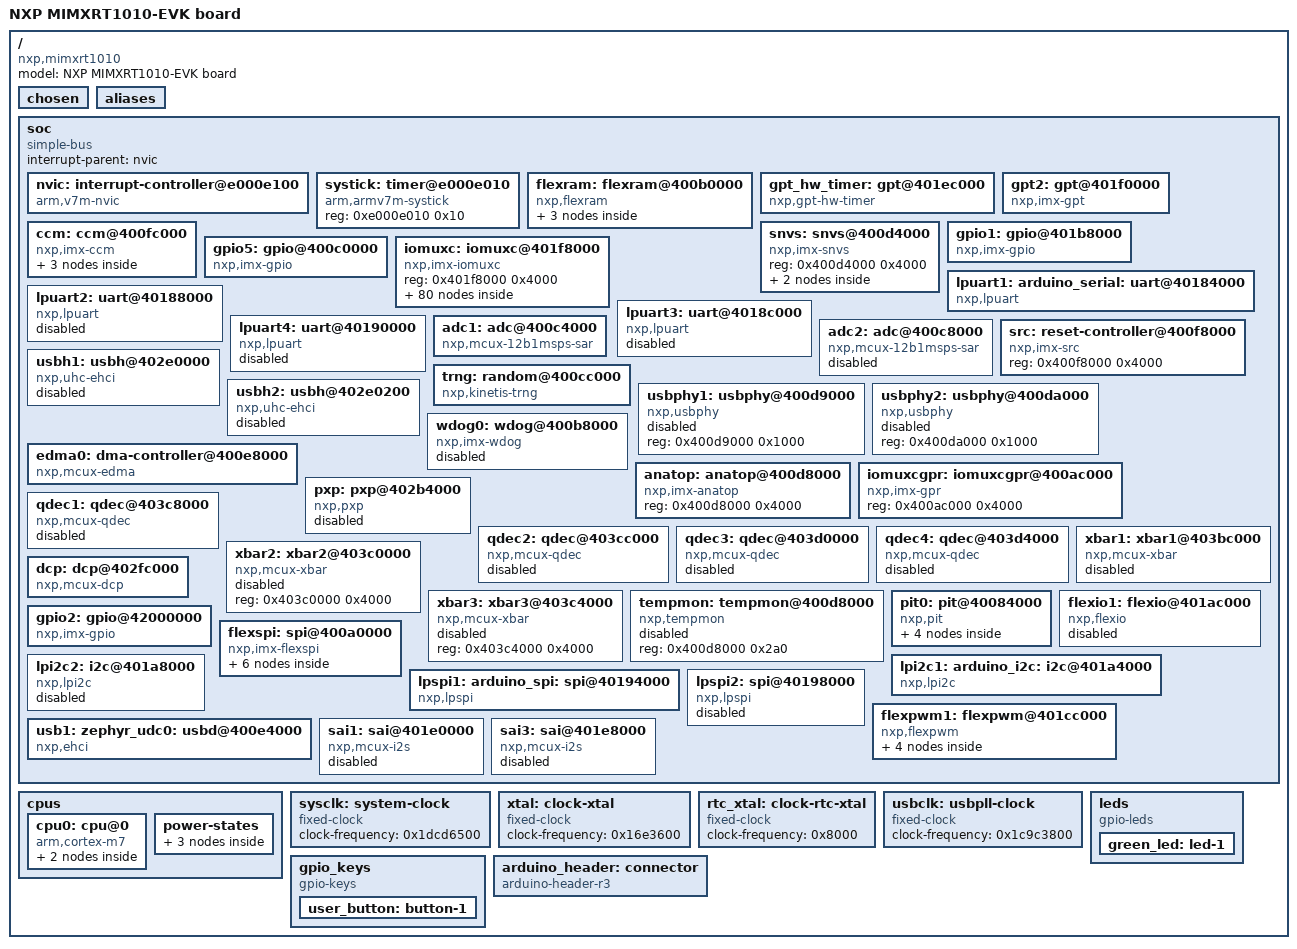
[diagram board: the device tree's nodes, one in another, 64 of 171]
/dts-v1/;

/* node '/' defined in zephyr/dts/common/skeleton.dtsi:9 */
/ {
	#address-cells = < 0x1 >;           /* in zephyr/dts/common/skeleton.dtsi:10 */
	#size-cells = < 0x1 >;              /* in zephyr/dts/common/skeleton.dtsi:11 */
	model = "NXP MIMXRT1010-EVK board"; /* in zephyr/boards/nxp/mimxrt1010_evk/mimxrt1010_evk.dts:16 */
	compatible = "nxp,mimxrt1010";      /* in zephyr/boards/nxp/mimxrt1010_evk/mimxrt1010_evk.dts:17 */

	/* node '/chosen' defined in zephyr/dts/common/skeleton.dtsi:13 */
	chosen {
		zephyr,entropy = &trng;                   /* in zephyr/dts/arm/nxp/nxp_rt10xx.dtsi:23 */
		zephyr,sram = &ocram;                     /* in zephyr/boards/nxp/mimxrt1010_evk/mimxrt1010_evk.dts:27 */
		zephyr,itcm = &itcm;                      /* in zephyr/boards/nxp/mimxrt1010_evk/mimxrt1010_evk.dts:28 */
		zephyr,dtcm = &dtcm;                      /* in zephyr/boards/nxp/mimxrt1010_evk/mimxrt1010_evk.dts:29 */
		zephyr,console = &lpuart1;                /* in zephyr/boards/nxp/mimxrt1010_evk/mimxrt1010_evk.dts:30 */
		zephyr,shell-uart = &lpuart1;             /* in zephyr/boards/nxp/mimxrt1010_evk/mimxrt1010_evk.dts:31 */
		zephyr,flash = &at25sf128a;               /* in zephyr/boards/nxp/mimxrt1010_evk/mimxrt1010_evk.dts:32 */
		zephyr,flash-controller = &at25sf128a;    /* in zephyr/boards/nxp/mimxrt1010_evk/mimxrt1010_evk.dts:33 */
		zephyr,code-partition = &slot0_partition; /* in zephyr/boards/nxp/mimxrt1010_evk/mimxrt1010_evk.dts:34 */
		zephyr,uart-mcumgr = &lpuart1;            /* in zephyr/boards/nxp/mimxrt1010_evk/mimxrt1010_evk.dts:35 */
	};

	/* node '/aliases' defined in zephyr/dts/common/skeleton.dtsi:15 */
	aliases {
		die-temp0 = &tempmon;           /* in zephyr/dts/arm/nxp/nxp_rt10xx.dtsi:19 */
		led0 = &green_led;              /* in zephyr/boards/nxp/mimxrt1010_evk/mimxrt1010_evk.dts:20 */
		sw0 = &user_button;             /* in zephyr/boards/nxp/mimxrt1010_evk/mimxrt1010_evk.dts:21 */
		mcuboot-button0 = &user_button; /* in zephyr/boards/nxp/mimxrt1010_evk/mimxrt1010_evk.dts:22 */
		rtc = &counter_rtc;             /* in zephyr/boards/nxp/mimxrt1010_evk/mimxrt1010_evk.dts:23 */
	};

	/* node '/soc' defined in zephyr/dts/arm/armv7-m.dtsi:6 */
	soc {
		#address-cells = < 0x1 >;     /* in zephyr/dts/arm/armv7-m.dtsi:7 */
		#size-cells = < 0x1 >;        /* in zephyr/dts/arm/armv7-m.dtsi:8 */
		compatible = "simple-bus";    /* in zephyr/dts/arm/armv7-m.dtsi:9 */
		interrupt-parent = < &nvic >; /* in zephyr/dts/arm/armv7-m.dtsi:10 */
		ranges;                       /* in zephyr/dts/arm/armv7-m.dtsi:11 */

		/* node '/soc/interrupt-controller@e000e100' defined in zephyr/dts/arm/armv7-m.dtsi:13 */
		nvic: interrupt-controller@e000e100 {
			#address-cells = < 0x1 >;            /* in zephyr/dts/arm/armv7-m.dtsi:14 */
			compatible = "arm,v7m-nvic";         /* in zephyr/dts/arm/armv7-m.dtsi:15 */
			reg = < 0xe000e100 0xc00 >;          /* in zephyr/dts/arm/armv7-m.dtsi:16 */
			interrupt-controller;                /* in zephyr/dts/arm/armv7-m.dtsi:17 */
			#interrupt-cells = < 0x2 >;          /* in zephyr/dts/arm/armv7-m.dtsi:18 */
			arm,num-irq-priority-bits = < 0x4 >; /* in zephyr/dts/arm/nxp/nxp_rt10xx.dtsi:1231 */
			phandle = < 0x1 >;                   /* in zephyr/dts/arm/armv7-m.dtsi:10 */
		};

		/* node '/soc/timer@e000e010' defined in zephyr/dts/arm/armv7-m.dtsi:21 */
		systick: timer@e000e010 {
			compatible = "arm,armv7m-systick"; /* in zephyr/dts/arm/armv7-m.dtsi:22 */
			reg = < 0xe000e010 0x10 >;         /* in zephyr/dts/arm/armv7-m.dtsi:23 */
			status = "okay";                   /* in zephyr/boards/nxp/mimxrt1010_evk/mimxrt1010_evk.dts:192 */
		};

		/* node '/soc/flexram@400b0000' defined in zephyr/dts/arm/nxp/nxp_rt10xx.dtsi:101 */
		flexram: flexram@400b0000 {
			compatible = "nxp,flexram";      /* in zephyr/dts/arm/nxp/nxp_rt10xx.dtsi:102 */
			reg = < 0x400b0000 0x4000 >;     /* in zephyr/dts/arm/nxp/nxp_rt10xx.dtsi:103 */
			interrupts = < 0x26 0x0 >;       /* in zephyr/dts/arm/nxp/nxp_rt10xx.dtsi:104 */
			#address-cells = < 0x1 >;        /* in zephyr/dts/arm/nxp/nxp_rt10xx.dtsi:106 */
			#size-cells = < 0x1 >;           /* in zephyr/dts/arm/nxp/nxp_rt10xx.dtsi:107 */
			status = "okay";                 /* in zephyr/dts/arm/nxp/nxp_rt10xx.dtsi:109 */
			flexram,bank-size = < 0x20 >;    /* in zephyr/dts/arm/nxp/nxp_rt10xx.dtsi:111 */
			flexram,num-ram-banks = < 0x4 >; /* in zephyr/dts/arm/nxp/nxp_rt1010.dtsi:10 */

			/* node '/soc/flexram@400b0000/itcm@0' defined in zephyr/dts/arm/nxp/nxp_rt10xx.dtsi:113 */
			itcm: itcm@0 {
				compatible = "zephyr,memory-region",
				             "nxp,imx-itcm";         /* in zephyr/dts/arm/nxp/nxp_rt10xx.dtsi:114 */
				zephyr,memory-region = "ITCM";       /* in zephyr/dts/arm/nxp/nxp_rt10xx.dtsi:116 */
				reg = < 0x0 0x8000 >;                /* in zephyr/dts/arm/nxp/nxp_rt1010.dtsi:18 */
			};

			/* node '/soc/flexram@400b0000/dtcm@20000000' defined in zephyr/dts/arm/nxp/nxp_rt10xx.dtsi:119 */
			dtcm: dtcm@20000000 {
				compatible = "zephyr,memory-region",
				             "nxp,imx-dtcm";         /* in zephyr/dts/arm/nxp/nxp_rt10xx.dtsi:120 */
				zephyr,memory-region = "DTCM";       /* in zephyr/dts/arm/nxp/nxp_rt10xx.dtsi:122 */
				reg = < 0x20000000 0x8000 >;         /* in zephyr/dts/arm/nxp/nxp_rt1010.dtsi:22 */
			};

			/* node '/soc/flexram@400b0000/ocram@20200000' defined in zephyr/dts/arm/nxp/nxp_rt10xx.dtsi:125 */
			ocram: ocram@20200000 {
				compatible = "zephyr,memory-region",
				             "mmio-sram";            /* in zephyr/dts/arm/nxp/nxp_rt10xx.dtsi:126 */
				zephyr,memory-region = "OCRAM";      /* in zephyr/dts/arm/nxp/nxp_rt10xx.dtsi:128 */
				reg = < 0x20200000 0x10000 >;        /* in zephyr/dts/arm/nxp/nxp_rt1010.dtsi:26 */
			};
		};

		/* node '/soc/gpt@401ec000' defined in zephyr/dts/arm/nxp/nxp_rt10xx.dtsi:165 */
		gpt_hw_timer: gpt@401ec000 {
			compatible = "nxp,gpt-hw-timer"; /* in zephyr/dts/arm/nxp/nxp_rt10xx.dtsi:166 */
			reg = < 0x401ec000 0x4000 >;     /* in zephyr/dts/arm/nxp/nxp_rt10xx.dtsi:167 */
			interrupts = < 0x1e 0x0 >;       /* in zephyr/dts/arm/nxp/nxp_rt1010.dtsi:46 */
			status = "okay";                 /* in zephyr/boards/nxp/mimxrt1010_evk/mimxrt1010_evk.dts:188 */
		};

		/* node '/soc/gpt@401f0000' defined in zephyr/dts/arm/nxp/nxp_rt10xx.dtsi:172 */
		gpt2: gpt@401f0000 {
			compatible = "nxp,imx-gpt";        /* in zephyr/dts/arm/nxp/nxp_rt10xx.dtsi:173 */
			reg = < 0x401f0000 0x4000 >;       /* in zephyr/dts/arm/nxp/nxp_rt10xx.dtsi:174 */
			clocks = < &ccm 0xa00 0x68 0x18 >; /* in zephyr/dts/arm/nxp/nxp_rt10xx.dtsi:177 */
			interrupts = < 0x1f 0x0 >;         /* in zephyr/dts/arm/nxp/nxp_rt1010.dtsi:50 */
			gptfreq = < 0xbebc20 >;            /* in zephyr/dts/arm/nxp/nxp_rt1010.dtsi:51 */
		};

		/* node '/soc/ccm@400fc000' defined in zephyr/dts/arm/nxp/nxp_rt10xx.dtsi:304 */
		ccm: ccm@400fc000 {
			compatible = "nxp,imx-ccm";  /* in zephyr/dts/arm/nxp/nxp_rt10xx.dtsi:305 */
			reg = < 0x400fc000 0x4000 >; /* in zephyr/dts/arm/nxp/nxp_rt10xx.dtsi:306 */
			clocks = < &xtal >,
			         < &rtc_xtal >;      /* in zephyr/dts/arm/nxp/nxp_rt10xx.dtsi:307 */
			clock-names = "xtal",
			              "rtc-xtal";    /* in zephyr/dts/arm/nxp/nxp_rt10xx.dtsi:308 */
			#clock-cells = < 0x3 >;      /* in zephyr/dts/arm/nxp/nxp_rt10xx.dtsi:337 */
			phandle = < 0x2 >;           /* in zephyr/dts/arm/nxp/nxp_rt10xx.dtsi:177 */

			/* node '/soc/ccm@400fc000/ahb-podf' defined in zephyr/dts/arm/nxp/nxp_rt10xx.dtsi:316 */
			ahb-podf {
				compatible = "fixed-factor-clock"; /* in zephyr/dts/arm/nxp/nxp_rt10xx.dtsi:317 */
				clock-div = < 0x1 >;               /* in zephyr/dts/arm/nxp/nxp_rt10xx.dtsi:318 */
				#clock-cells = < 0x0 >;            /* in zephyr/dts/arm/nxp/nxp_rt10xx.dtsi:319 */
			};

			/* node '/soc/ccm@400fc000/ipg-podf' defined in zephyr/dts/arm/nxp/nxp_rt10xx.dtsi:322 */
			ipg-podf {
				compatible = "fixed-factor-clock"; /* in zephyr/dts/arm/nxp/nxp_rt10xx.dtsi:323 */
				#clock-cells = < 0x0 >;            /* in zephyr/dts/arm/nxp/nxp_rt10xx.dtsi:325 */
				clock-div = < 0x4 >;               /* in zephyr/dts/arm/nxp/nxp_rt1010.dtsi:33 */
			};

			/* node '/soc/ccm@400fc000/sys-pll' defined in zephyr/dts/arm/nxp/nxp_rt10xx.dtsi:328 */
			sys-pll {
				compatible = "nxp,imx-ccm-fnpll"; /* in zephyr/dts/arm/nxp/nxp_rt10xx.dtsi:329 */
				loop-div = < 0x16 >;              /* in zephyr/dts/arm/nxp/nxp_rt10xx.dtsi:330 */
				numerator = < 0x0 >;              /* in zephyr/dts/arm/nxp/nxp_rt10xx.dtsi:331 */
				denominator = < 0x1 >;            /* in zephyr/dts/arm/nxp/nxp_rt10xx.dtsi:332 */
				src = < 0x0 >;                    /* in zephyr/dts/arm/nxp/nxp_rt10xx.dtsi:333 */
				#clock-cells = < 0x0 >;           /* in zephyr/dts/arm/nxp/nxp_rt10xx.dtsi:334 */
			};
		};

		/* node '/soc/snvs@400d4000' defined in zephyr/dts/arm/nxp/nxp_rt10xx.dtsi:340 */
		snvs: snvs@400d4000 {
			compatible = "nxp,imx-snvs"; /* in zephyr/dts/arm/nxp/nxp_rt10xx.dtsi:341 */
			reg = < 0x400d4000 0x4000 >; /* in zephyr/dts/arm/nxp/nxp_rt10xx.dtsi:342 */

			/* node '/soc/snvs@400d4000/rtc' defined in zephyr/dts/arm/nxp/nxp_rt10xx.dtsi:344 */
			snvs_rtc: rtc {
				compatible = "nxp,imx-snvs-rtc"; /* in zephyr/dts/arm/nxp/nxp_rt10xx.dtsi:345 */
				interrupts = < 0x2e 0x0 >;       /* in zephyr/dts/arm/nxp/nxp_rt10xx.dtsi:346 */
				wakeup-source;                   /* in zephyr/dts/arm/nxp/nxp_rt10xx.dtsi:347 */

				/* node '/soc/snvs@400d4000/rtc/counter_rtc' defined in zephyr/dts/arm/nxp/nxp_rt10xx.dtsi:349 */
				counter_rtc: counter_rtc {
					compatible = "zephyr,rtc-counter"; /* in zephyr/dts/arm/nxp/nxp_rt10xx.dtsi:350 */
					alarms-count = < 0x2 >;            /* in zephyr/dts/arm/nxp/nxp_rt10xx.dtsi:351 */
					status = "okay";                   /* in zephyr/boards/nxp/mimxrt1010_evk/mimxrt1010_evk.dts:200 */
				};
			};
		};

		/* node '/soc/gpio@401b8000' defined in zephyr/dts/arm/nxp/nxp_rt10xx.dtsi:357 */
		gpio1: gpio@401b8000 {
			compatible = "nxp,imx-gpio";                  /* in zephyr/dts/arm/nxp/nxp_rt10xx.dtsi:358 */
			reg = < 0x401b8000 0x4000 >;                  /* in zephyr/dts/arm/nxp/nxp_rt10xx.dtsi:359 */
			gpio-controller;                              /* in zephyr/dts/arm/nxp/nxp_rt10xx.dtsi:361 */
			#gpio-cells = < 0x2 >;                        /* in zephyr/dts/arm/nxp/nxp_rt10xx.dtsi:362 */
			interrupts = < 0x46 0x0 >,
			             < 0x47 0x0 >;                    /* in zephyr/dts/arm/nxp/nxp_rt1010.dtsi:38 */
			pinmux = < &iomuxc_gpio_00_gpiomux_io00 >,
			         < &iomuxc_gpio_01_gpiomux_io01 >,
			         < &iomuxc_gpio_02_gpiomux_io02 >,
			         < &iomuxc_gpio_03_gpiomux_io03 >,
			         < &iomuxc_gpio_04_gpiomux_io04 >,
			         < &iomuxc_gpio_05_gpiomux_io05 >,
			         < &iomuxc_gpio_06_gpiomux_io06 >,
			         < &iomuxc_gpio_07_gpiomux_io07 >,
			         < &iomuxc_gpio_08_gpiomux_io08 >,
			         < &iomuxc_gpio_09_gpiomux_io09 >,
			         < &iomuxc_gpio_10_gpiomux_io10 >,
			         < &iomuxc_gpio_11_gpiomux_io11 >,
			         < &iomuxc_gpio_12_gpiomux_io12 >,
			         < &iomuxc_gpio_13_gpiomux_io13 >,
			         < &iomuxc_gpio_ad_00_gpiomux_io14 >,
			         < &iomuxc_gpio_ad_01_gpiomux_io15 >,
			         < &iomuxc_gpio_ad_02_gpiomux_io16 >,
			         < &iomuxc_gpio_ad_03_gpiomux_io17 >,
			         < &iomuxc_gpio_ad_04_gpiomux_io18 >,
			         < &iomuxc_gpio_ad_05_gpiomux_io19 >,
			         < &iomuxc_gpio_ad_06_gpiomux_io20 >,
			         < &iomuxc_gpio_ad_07_gpiomux_io21 >,
			         < &iomuxc_gpio_ad_08_gpiomux_io22 >,
			         < &iomuxc_gpio_ad_09_gpiomux_io23 >,
			         < &iomuxc_gpio_ad_10_gpiomux_io24 >,
			         < &iomuxc_gpio_ad_11_gpiomux_io25 >,
			         < &iomuxc_gpio_ad_12_gpiomux_io26 >,
			         < &iomuxc_gpio_ad_13_gpiomux_io27 >,
			         < &iomuxc_gpio_ad_14_gpiomux_io28 >; /* in zephyr/dts/arm/nxp/nxp_rt1010.dtsi:360 */
			phandle = < 0x51 >;                           /* in zephyr/boards/nxp/mimxrt1010_evk/mimxrt1010_evk.dts:42 */
		};

		/* node '/soc/gpio@400c0000' defined in zephyr/dts/arm/nxp/nxp_rt10xx.dtsi:389 */
		gpio5: gpio@400c0000 {
			compatible = "nxp,imx-gpio";                      /* in zephyr/dts/arm/nxp/nxp_rt10xx.dtsi:390 */
			reg = < 0x400c0000 0x4000 >;                      /* in zephyr/dts/arm/nxp/nxp_rt10xx.dtsi:391 */
			gpio-controller;                                  /* in zephyr/dts/arm/nxp/nxp_rt10xx.dtsi:393 */
			#gpio-cells = < 0x2 >;                            /* in zephyr/dts/arm/nxp/nxp_rt10xx.dtsi:394 */
			interrupts = < 0x49 0x0 >;                        /* in zephyr/dts/arm/nxp/nxp_rt1010.dtsi:42 */
			pinmux = < &iomuxc_snvs_pmic_on_req_gpio5_io00 >; /* in zephyr/dts/arm/nxp/nxp_rt1010.dtsi:392 */
		};

		/* node '/soc/iomuxc@401f8000' defined in zephyr/dts/arm/nxp/nxp_rt10xx.dtsi:473 */
		iomuxc: iomuxc@401f8000 {
			compatible = "nxp,imx-iomuxc"; /* in zephyr/dts/arm/nxp/nxp_rt10xx.dtsi:474 */
			reg = < 0x401f8000 0x4000 >;   /* in zephyr/dts/arm/nxp/nxp_rt10xx.dtsi:475 */
			status = "okay";               /* in zephyr/dts/arm/nxp/nxp_rt10xx.dtsi:476 */

			/* node '/soc/iomuxc@401f8000/pinctrl' defined in zephyr/dts/arm/nxp/nxp_rt10xx.dtsi:478 */
			pinctrl: pinctrl {
				status = "okay";                    /* in zephyr/dts/arm/nxp/nxp_rt10xx.dtsi:479 */
				compatible = "nxp,mcux-rt-pinctrl"; /* in zephyr/dts/arm/nxp/nxp_rt10xx.dtsi:480 */

				/* node '/soc/iomuxc@401f8000/pinctrl/pinmux_adc1' defined in zephyr/boards/nxp/mimxrt1010_evk/mimxrt1010_evk-pinctrl.dtsi:13 */
				pinmux_adc1: pinmux_adc1 {
					phandle = < 0x39 >; /* in zephyr/boards/nxp/mimxrt1010_evk/mimxrt1010_evk.dts:170 */

					/* node '/soc/iomuxc@401f8000/pinctrl/pinmux_adc1/group0' defined in zephyr/boards/nxp/mimxrt1010_evk/mimxrt1010_evk-pinctrl.dtsi:14 */
					group0 {
						pinmux = < &iomuxc_gpio_ad_01_adc1_in1 >,
						         < &iomuxc_gpio_ad_02_adc1_in2 >; /* in zephyr/boards/nxp/mimxrt1010_evk/mimxrt1010_evk-pinctrl.dtsi:15 */
						drive-strength = "r0-4";                  /* in zephyr/boards/nxp/mimxrt1010_evk/mimxrt1010_evk-pinctrl.dtsi:17 */
						slew-rate = "slow";                       /* in zephyr/boards/nxp/mimxrt1010_evk/mimxrt1010_evk-pinctrl.dtsi:18 */
						nxp,speed = "100-mhz";                    /* in zephyr/boards/nxp/mimxrt1010_evk/mimxrt1010_evk-pinctrl.dtsi:19 */
					};
				};

				/* node '/soc/iomuxc@401f8000/pinctrl/pinmux_lpi2c1' defined in zephyr/boards/nxp/mimxrt1010_evk/mimxrt1010_evk-pinctrl.dtsi:23 */
				pinmux_lpi2c1: pinmux_lpi2c1 {
					phandle = < 0x49 >; /* in zephyr/boards/nxp/mimxrt1010_evk/mimxrt1010_evk.dts:143 */

					/* node '/soc/iomuxc@401f8000/pinctrl/pinmux_lpi2c1/group0' defined in zephyr/boards/nxp/mimxrt1010_evk/mimxrt1010_evk-pinctrl.dtsi:24 */
					group0 {
						pinmux = < &iomuxc_gpio_01_lpi2c1_sda >,
						         < &iomuxc_gpio_02_lpi2c1_scl >; /* in zephyr/boards/nxp/mimxrt1010_evk/mimxrt1010_evk-pinctrl.dtsi:25 */
						drive-strength = "r0-4";                 /* in zephyr/boards/nxp/mimxrt1010_evk/mimxrt1010_evk-pinctrl.dtsi:26 */
						drive-open-drain;                        /* in zephyr/boards/nxp/mimxrt1010_evk/mimxrt1010_evk-pinctrl.dtsi:27 */
						slew-rate = "slow";                      /* in zephyr/boards/nxp/mimxrt1010_evk/mimxrt1010_evk-pinctrl.dtsi:28 */
						nxp,speed = "100-mhz";                   /* in zephyr/boards/nxp/mimxrt1010_evk/mimxrt1010_evk-pinctrl.dtsi:29 */
						input-enable;                            /* in zephyr/boards/nxp/mimxrt1010_evk/mimxrt1010_evk-pinctrl.dtsi:30 */
					};
				};

				/* node '/soc/iomuxc@401f8000/pinctrl/pinmux_lpspi1' defined in zephyr/boards/nxp/mimxrt1010_evk/mimxrt1010_evk-pinctrl.dtsi:34 */
				pinmux_lpspi1: pinmux_lpspi1 {
					phandle = < 0x4a >; /* in zephyr/boards/nxp/mimxrt1010_evk/mimxrt1010_evk.dts:160 */

					/* node '/soc/iomuxc@401f8000/pinctrl/pinmux_lpspi1/group0' defined in zephyr/boards/nxp/mimxrt1010_evk/mimxrt1010_evk-pinctrl.dtsi:35 */
					group0 {
						pinmux = < &iomuxc_gpio_ad_06_lpspi1_sck >,
						         < &iomuxc_gpio_ad_05_lpspi1_pcs0 >,
						         < &iomuxc_gpio_ad_04_lpspi1_sdo >,
						         < &iomuxc_gpio_ad_03_lpspi1_sdi >;  /* in zephyr/boards/nxp/mimxrt1010_evk/mimxrt1010_evk-pinctrl.dtsi:36 */
						drive-strength = "r0-4";                     /* in zephyr/boards/nxp/mimxrt1010_evk/mimxrt1010_evk-pinctrl.dtsi:40 */
						slew-rate = "slow";                          /* in zephyr/boards/nxp/mimxrt1010_evk/mimxrt1010_evk-pinctrl.dtsi:41 */
						nxp,speed = "100-mhz";                       /* in zephyr/boards/nxp/mimxrt1010_evk/mimxrt1010_evk-pinctrl.dtsi:42 */
					};
				};

				/* node '/soc/iomuxc@401f8000/pinctrl/pinmux_lpuart1' defined in zephyr/boards/nxp/mimxrt1010_evk/mimxrt1010_evk-pinctrl.dtsi:47 */
				pinmux_lpuart1: pinmux_lpuart1 {
					phandle = < 0x35 >; /* in zephyr/boards/nxp/mimxrt1010_evk/mimxrt1010_evk.dts:150 */

					/* node '/soc/iomuxc@401f8000/pinctrl/pinmux_lpuart1/group0' defined in zephyr/boards/nxp/mimxrt1010_evk/mimxrt1010_evk-pinctrl.dtsi:48 */
					group0 {
						pinmux = < &iomuxc_gpio_09_lpuart1_rxd >,
						         < &iomuxc_gpio_10_lpuart1_txd >; /* in zephyr/boards/nxp/mimxrt1010_evk/mimxrt1010_evk-pinctrl.dtsi:49 */
						drive-strength = "r0-4";                  /* in zephyr/boards/nxp/mimxrt1010_evk/mimxrt1010_evk-pinctrl.dtsi:51 */
						slew-rate = "slow";                       /* in zephyr/boards/nxp/mimxrt1010_evk/mimxrt1010_evk-pinctrl.dtsi:52 */
						nxp,speed = "100-mhz";                    /* in zephyr/boards/nxp/mimxrt1010_evk/mimxrt1010_evk-pinctrl.dtsi:53 */
					};
				};

				/* node '/soc/iomuxc@401f8000/pinctrl/pinmux_lpuart1_sleep' defined in zephyr/boards/nxp/mimxrt1010_evk/mimxrt1010_evk-pinctrl.dtsi:57 */
				pinmux_lpuart1_sleep: pinmux_lpuart1_sleep {
					phandle = < 0x36 >; /* in zephyr/boards/nxp/mimxrt1010_evk/mimxrt1010_evk.dts:151 */

					/* node '/soc/iomuxc@401f8000/pinctrl/pinmux_lpuart1_sleep/group0' defined in zephyr/boards/nxp/mimxrt1010_evk/mimxrt1010_evk-pinctrl.dtsi:58 */
					group0 {
						pinmux = < &iomuxc_gpio_09_gpiomux_io09 >; /* in zephyr/boards/nxp/mimxrt1010_evk/mimxrt1010_evk-pinctrl.dtsi:59 */
						drive-strength = "r0-4";                   /* in zephyr/boards/nxp/mimxrt1010_evk/mimxrt1010_evk-pinctrl.dtsi:60 */
						bias-pull-up;                              /* in zephyr/boards/nxp/mimxrt1010_evk/mimxrt1010_evk-pinctrl.dtsi:61 */
						bias-pull-up-value = "100k";               /* in zephyr/boards/nxp/mimxrt1010_evk/mimxrt1010_evk-pinctrl.dtsi:62 */
						slew-rate = "slow";                        /* in zephyr/boards/nxp/mimxrt1010_evk/mimxrt1010_evk-pinctrl.dtsi:63 */
						nxp,speed = "100-mhz";                     /* in zephyr/boards/nxp/mimxrt1010_evk/mimxrt1010_evk-pinctrl.dtsi:64 */
					};

					/* node '/soc/iomuxc@401f8000/pinctrl/pinmux_lpuart1_sleep/group1' defined in zephyr/boards/nxp/mimxrt1010_evk/mimxrt1010_evk-pinctrl.dtsi:67 */
					group1 {
						pinmux = < &iomuxc_gpio_10_lpuart1_txd >; /* in zephyr/boards/nxp/mimxrt1010_evk/mimxrt1010_evk-pinctrl.dtsi:68 */
						drive-strength = "r0-4";                  /* in zephyr/boards/nxp/mimxrt1010_evk/mimxrt1010_evk-pinctrl.dtsi:69 */
						slew-rate = "slow";                       /* in zephyr/boards/nxp/mimxrt1010_evk/mimxrt1010_evk-pinctrl.dtsi:70 */
						nxp,speed = "100-mhz";                    /* in zephyr/boards/nxp/mimxrt1010_evk/mimxrt1010_evk-pinctrl.dtsi:71 */
					};
				};

				/* node '/soc/iomuxc@401f8000/pinctrl/pinmux_lpuart4' defined in zephyr/boards/nxp/mimxrt1010_evk/mimxrt1010_evk-pinctrl.dtsi:76 */
				pinmux_lpuart4: pinmux_lpuart4 {
					phandle = < 0x37 >; /* in zephyr/boards/nxp/mimxrt1010_evk/mimxrt1010_evk.dts:90 */

					/* node '/soc/iomuxc@401f8000/pinctrl/pinmux_lpuart4/group0' defined in zephyr/boards/nxp/mimxrt1010_evk/mimxrt1010_evk-pinctrl.dtsi:77 */
					group0 {
						pinmux = < &iomuxc_gpio_ad_01_lpuart4_rxd >,
						         < &iomuxc_gpio_ad_02_lpuart4_txd >; /* in zephyr/boards/nxp/mimxrt1010_evk/mimxrt1010_evk-pinctrl.dtsi:78 */
						drive-strength = "r0-4";                     /* in zephyr/boards/nxp/mimxrt1010_evk/mimxrt1010_evk-pinctrl.dtsi:80 */
						slew-rate = "slow";                          /* in zephyr/boards/nxp/mimxrt1010_evk/mimxrt1010_evk-pinctrl.dtsi:81 */
						nxp,speed = "100-mhz";                       /* in zephyr/boards/nxp/mimxrt1010_evk/mimxrt1010_evk-pinctrl.dtsi:82 */
					};
				};

				/* node '/soc/iomuxc@401f8000/pinctrl/pinmux_lpuart4_sleep' defined in zephyr/boards/nxp/mimxrt1010_evk/mimxrt1010_evk-pinctrl.dtsi:87 */
				pinmux_lpuart4_sleep: pinmux_lpuart4_sleep {
					phandle = < 0x38 >; /* in zephyr/boards/nxp/mimxrt1010_evk/mimxrt1010_evk.dts:91 */

					/* node '/soc/iomuxc@401f8000/pinctrl/pinmux_lpuart4_sleep/group0' defined in zephyr/boards/nxp/mimxrt1010_evk/mimxrt1010_evk-pinctrl.dtsi:88 */
					group0 {
						pinmux = < &iomuxc_gpio_ad_01_gpiomux_io15 >; /* in zephyr/boards/nxp/mimxrt1010_evk/mimxrt1010_evk-pinctrl.dtsi:89 */
						drive-strength = "r0-4";                      /* in zephyr/boards/nxp/mimxrt1010_evk/mimxrt1010_evk-pinctrl.dtsi:90 */
						bias-pull-up;                                 /* in zephyr/boards/nxp/mimxrt1010_evk/mimxrt1010_evk-pinctrl.dtsi:91 */
						bias-pull-up-value = "100k";                  /* in zephyr/boards/nxp/mimxrt1010_evk/mimxrt1010_evk-pinctrl.dtsi:92 */
						slew-rate = "slow";                           /* in zephyr/boards/nxp/mimxrt1010_evk/mimxrt1010_evk-pinctrl.dtsi:93 */
						nxp,speed = "100-mhz";                        /* in zephyr/boards/nxp/mimxrt1010_evk/mimxrt1010_evk-pinctrl.dtsi:94 */
					};

					/* node '/soc/iomuxc@401f8000/pinctrl/pinmux_lpuart4_sleep/group1' defined in zephyr/boards/nxp/mimxrt1010_evk/mimxrt1010_evk-pinctrl.dtsi:97 */
					group1 {
						pinmux = < &iomuxc_gpio_ad_02_lpuart4_txd >; /* in zephyr/boards/nxp/mimxrt1010_evk/mimxrt1010_evk-pinctrl.dtsi:98 */
						drive-strength = "r0-4";                     /* in zephyr/boards/nxp/mimxrt1010_evk/mimxrt1010_evk-pinctrl.dtsi:99 */
						slew-rate = "slow";                          /* in zephyr/boards/nxp/mimxrt1010_evk/mimxrt1010_evk-pinctrl.dtsi:100 */
						nxp,speed = "100-mhz";                       /* in zephyr/boards/nxp/mimxrt1010_evk/mimxrt1010_evk-pinctrl.dtsi:101 */
					};
				};

				/* node '/soc/iomuxc@401f8000/pinctrl/pinmux_sai1' defined in zephyr/boards/nxp/mimxrt1010_evk/mimxrt1010_evk-pinctrl.dtsi:105 */
				pinmux_sai1: pinmux_sai1 {
					phandle = < 0x4d >; /* in zephyr/boards/nxp/mimxrt1010_evk/mimxrt1010_evk.dts:175 */

					/* node '/soc/iomuxc@401f8000/pinctrl/pinmux_sai1/group0' defined in zephyr/boards/nxp/mimxrt1010_evk/mimxrt1010_evk-pinctrl.dtsi:106 */
					group0 {
						pinmux = < &iomuxc_gpio_08_sai1_mclk >,
						         < &iomuxc_gpio_03_sai1_rx_data0 >,
						         < &iomuxc_gpio_04_sai1_tx_data0 >,
						         < &iomuxc_gpio_07_sai1_tx_sync >,
						         < &iomuxc_gpio_06_sai1_tx_bclk >;  /* in zephyr/boards/nxp/mimxrt1010_evk/mimxrt1010_evk-pinctrl.dtsi:107 */
						drive-strength = "r0-4";                    /* in zephyr/boards/nxp/mimxrt1010_evk/mimxrt1010_evk-pinctrl.dtsi:112 */
						slew-rate = "slow";                         /* in zephyr/boards/nxp/mimxrt1010_evk/mimxrt1010_evk-pinctrl.dtsi:113 */
						nxp,speed = "100-mhz";                      /* in zephyr/boards/nxp/mimxrt1010_evk/mimxrt1010_evk-pinctrl.dtsi:114 */
					};
				};
			};

			/* node '/soc/iomuxc@401f8000/IOMUXC_GPIO_00_GPIOMUX_IO00' defined in modules/hal/nxp/dts/nxp/nxp_imx/rt/mimxrt1011dae5a-pinctrl.dtsi:24 */
			iomuxc_gpio_00_gpiomux_io00: IOMUXC_GPIO_00_GPIOMUX_IO00 {
				pinmux = < 0x401f80bc 0x5 0x0 0x0 0x401f816c >; /* in modules/hal/nxp/dts/nxp/nxp_imx/rt/mimxrt1011dae5a-pinctrl.dtsi:25 */
				phandle = < 0x5 >;                              /* in zephyr/dts/arm/nxp/nxp_rt1010.dtsi:360 */
			};

			/* node '/soc/iomuxc@401f8000/IOMUXC_GPIO_01_GPIOMUX_IO01' defined in modules/hal/nxp/dts/nxp/nxp_imx/rt/mimxrt1011dae5a-pinctrl.dtsi:42 */
			iomuxc_gpio_01_gpiomux_io01: IOMUXC_GPIO_01_GPIOMUX_IO01 {
				pinmux = < 0x401f80b8 0x5 0x0 0x0 0x401f8168 >; /* in modules/hal/nxp/dts/nxp/nxp_imx/rt/mimxrt1011dae5a-pinctrl.dtsi:43 */
				phandle = < 0x6 >;                              /* in zephyr/dts/arm/nxp/nxp_rt1010.dtsi:360 */
			};

			/* node '/soc/iomuxc@401f8000/IOMUXC_GPIO_01_LPI2C1_SDA' defined in modules/hal/nxp/dts/nxp/nxp_imx/rt/mimxrt1011dae5a-pinctrl.dtsi:48 */
			iomuxc_gpio_01_lpi2c1_sda: IOMUXC_GPIO_01_LPI2C1_SDA {
				pinmux = < 0x401f80b8 0x3 0x401f81c4 0x3 0x401f8168 >; /* in modules/hal/nxp/dts/nxp/nxp_imx/rt/mimxrt1011dae5a-pinctrl.dtsi:49 */
				phandle = < 0x25 >;                                    /* in zephyr/boards/nxp/mimxrt1010_evk/mimxrt1010_evk-pinctrl.dtsi:25 */
			};

			/* node '/soc/iomuxc@401f8000/IOMUXC_GPIO_02_GPIOMUX_IO02' defined in modules/hal/nxp/dts/nxp/nxp_imx/rt/mimxrt1011dae5a-pinctrl.dtsi:60 */
			iomuxc_gpio_02_gpiomux_io02: IOMUXC_GPIO_02_GPIOMUX_IO02 {
				pinmux = < 0x401f80b4 0x5 0x0 0x0 0x401f8164 >; /* in modules/hal/nxp/dts/nxp/nxp_imx/rt/mimxrt1011dae5a-pinctrl.dtsi:61 */
				phandle = < 0x7 >;                              /* in zephyr/dts/arm/nxp/nxp_rt1010.dtsi:360 */
			};

			/* node '/soc/iomuxc@401f8000/IOMUXC_GPIO_02_LPI2C1_SCL' defined in modules/hal/nxp/dts/nxp/nxp_imx/rt/mimxrt1011dae5a-pinctrl.dtsi:66 */
			iomuxc_gpio_02_lpi2c1_scl: IOMUXC_GPIO_02_LPI2C1_SCL {
				pinmux = < 0x401f80b4 0x3 0x401f81c0 0x3 0x401f8164 >; /* in modules/hal/nxp/dts/nxp/nxp_imx/rt/mimxrt1011dae5a-pinctrl.dtsi:67 */
				phandle = < 0x26 >;                                    /* in zephyr/boards/nxp/mimxrt1010_evk/mimxrt1010_evk-pinctrl.dtsi:25 */
			};

			/* node '/soc/iomuxc@401f8000/IOMUXC_GPIO_03_GPIOMUX_IO03' defined in modules/hal/nxp/dts/nxp/nxp_imx/rt/mimxrt1011dae5a-pinctrl.dtsi:78 */
			iomuxc_gpio_03_gpiomux_io03: IOMUXC_GPIO_03_GPIOMUX_IO03 {
				pinmux = < 0x401f80b0 0x5 0x0 0x0 0x401f8160 >; /* in modules/hal/nxp/dts/nxp/nxp_imx/rt/mimxrt1011dae5a-pinctrl.dtsi:79 */
				phandle = < 0x8 >;                              /* in zephyr/dts/arm/nxp/nxp_rt1010.dtsi:360 */
			};

			/* node '/soc/iomuxc@401f8000/IOMUXC_GPIO_03_SAI1_RX_DATA0' defined in modules/hal/nxp/dts/nxp/nxp_imx/rt/mimxrt1011dae5a-pinctrl.dtsi:84 */
			iomuxc_gpio_03_sai1_rx_data0: IOMUXC_GPIO_03_SAI1_RX_DATA0 {
				pinmux = < 0x401f80b0 0x0 0x0 0x0 0x401f8160 >; /* in modules/hal/nxp/dts/nxp/nxp_imx/rt/mimxrt1011dae5a-pinctrl.dtsi:85 */
				phandle = < 0x30 >;                             /* in zephyr/boards/nxp/mimxrt1010_evk/mimxrt1010_evk-pinctrl.dtsi:107 */
			};

			/* node '/soc/iomuxc@401f8000/IOMUXC_GPIO_04_GPIOMUX_IO04' defined in modules/hal/nxp/dts/nxp/nxp_imx/rt/mimxrt1011dae5a-pinctrl.dtsi:93 */
			iomuxc_gpio_04_gpiomux_io04: IOMUXC_GPIO_04_GPIOMUX_IO04 {
				pinmux = < 0x401f80ac 0x5 0x0 0x0 0x401f815c >; /* in modules/hal/nxp/dts/nxp/nxp_imx/rt/mimxrt1011dae5a-pinctrl.dtsi:94 */
				phandle = < 0x9 >;                              /* in zephyr/dts/arm/nxp/nxp_rt1010.dtsi:360 */
			};

			/* node '/soc/iomuxc@401f8000/IOMUXC_GPIO_04_SAI1_TX_DATA0' defined in modules/hal/nxp/dts/nxp/nxp_imx/rt/mimxrt1011dae5a-pinctrl.dtsi:99 */
			iomuxc_gpio_04_sai1_tx_data0: IOMUXC_GPIO_04_SAI1_TX_DATA0 {
				pinmux = < 0x401f80ac 0x0 0x0 0x0 0x401f815c >; /* in modules/hal/nxp/dts/nxp/nxp_imx/rt/mimxrt1011dae5a-pinctrl.dtsi:100 */
				phandle = < 0x31 >;                             /* in zephyr/boards/nxp/mimxrt1010_evk/mimxrt1010_evk-pinctrl.dtsi:107 */
			};

			/* node '/soc/iomuxc@401f8000/IOMUXC_GPIO_05_GPIOMUX_IO05' defined in modules/hal/nxp/dts/nxp/nxp_imx/rt/mimxrt1011dae5a-pinctrl.dtsi:108 */
			iomuxc_gpio_05_gpiomux_io05: IOMUXC_GPIO_05_GPIOMUX_IO05 {
				pinmux = < 0x401f80a8 0x5 0x0 0x0 0x401f8158 >; /* in modules/hal/nxp/dts/nxp/nxp_imx/rt/mimxrt1011dae5a-pinctrl.dtsi:109 */
				phandle = < 0xa >;                              /* in zephyr/dts/arm/nxp/nxp_rt1010.dtsi:360 */
			};

			/* node '/soc/iomuxc@401f8000/IOMUXC_GPIO_06_GPIOMUX_IO06' defined in modules/hal/nxp/dts/nxp/nxp_imx/rt/mimxrt1011dae5a-pinctrl.dtsi:126 */
			iomuxc_gpio_06_gpiomux_io06: IOMUXC_GPIO_06_GPIOMUX_IO06 {
				pinmux = < 0x401f80a4 0x5 0x0 0x0 0x401f8154 >; /* in modules/hal/nxp/dts/nxp/nxp_imx/rt/mimxrt1011dae5a-pinctrl.dtsi:127 */
				phandle = < 0xb >;                              /* in zephyr/dts/arm/nxp/nxp_rt1010.dtsi:360 */
			};

			/* node '/soc/iomuxc@401f8000/IOMUXC_GPIO_06_SAI1_TX_BCLK' defined in modules/hal/nxp/dts/nxp/nxp_imx/rt/mimxrt1011dae5a-pinctrl.dtsi:135 */
			iomuxc_gpio_06_sai1_tx_bclk: IOMUXC_GPIO_06_SAI1_TX_BCLK {
				pinmux = < 0x401f80a4 0x0 0x0 0x0 0x401f8154 >; /* in modules/hal/nxp/dts/nxp/nxp_imx/rt/mimxrt1011dae5a-pinctrl.dtsi:136 */
				phandle = < 0x33 >;                             /* in zephyr/boards/nxp/mimxrt1010_evk/mimxrt1010_evk-pinctrl.dtsi:107 */
			};

			/* node '/soc/iomuxc@401f8000/IOMUXC_GPIO_07_GPIOMUX_IO07' defined in modules/hal/nxp/dts/nxp/nxp_imx/rt/mimxrt1011dae5a-pinctrl.dtsi:144 */
			iomuxc_gpio_07_gpiomux_io07: IOMUXC_GPIO_07_GPIOMUX_IO07 {
				pinmux = < 0x401f80a0 0x5 0x0 0x0 0x401f8150 >; /* in modules/hal/nxp/dts/nxp/nxp_imx/rt/mimxrt1011dae5a-pinctrl.dtsi:145 */
				phandle = < 0xc >;                              /* in zephyr/dts/arm/nxp/nxp_rt1010.dtsi:360 */
			};

			/* node '/soc/iomuxc@401f8000/IOMUXC_GPIO_07_SAI1_TX_SYNC' defined in modules/hal/nxp/dts/nxp/nxp_imx/rt/mimxrt1011dae5a-pinctrl.dtsi:156 */
			iomuxc_gpio_07_sai1_tx_sync: IOMUXC_GPIO_07_SAI1_TX_SYNC {
				pinmux = < 0x401f80a0 0x0 0x0 0x0 0x401f8150 >; /* in modules/hal/nxp/dts/nxp/nxp_imx/rt/mimxrt1011dae5a-pinctrl.dtsi:157 */
				phandle = < 0x32 >;                             /* in zephyr/boards/nxp/mimxrt1010_evk/mimxrt1010_evk-pinctrl.dtsi:107 */
			};

			/* node '/soc/iomuxc@401f8000/IOMUXC_GPIO_08_GPIOMUX_IO08' defined in modules/hal/nxp/dts/nxp/nxp_imx/rt/mimxrt1011dae5a-pinctrl.dtsi:168 */
			iomuxc_gpio_08_gpiomux_io08: IOMUXC_GPIO_08_GPIOMUX_IO08 {
				pinmux = < 0x401f809c 0x5 0x0 0x0 0x401f814c >; /* in modules/hal/nxp/dts/nxp/nxp_imx/rt/mimxrt1011dae5a-pinctrl.dtsi:169 */
				phandle = < 0xd >;                              /* in zephyr/dts/arm/nxp/nxp_rt1010.dtsi:360 */
			};

			/* node '/soc/iomuxc@401f8000/IOMUXC_GPIO_08_SAI1_MCLK' defined in modules/hal/nxp/dts/nxp/nxp_imx/rt/mimxrt1011dae5a-pinctrl.dtsi:180 */
			iomuxc_gpio_08_sai1_mclk: IOMUXC_GPIO_08_SAI1_MCLK {
				pinmux = < 0x401f809c 0x0 0x0 0x0 0x401f814c >; /* in modules/hal/nxp/dts/nxp/nxp_imx/rt/mimxrt1011dae5a-pinctrl.dtsi:181 */
				phandle = < 0x2f >;                             /* in zephyr/boards/nxp/mimxrt1010_evk/mimxrt1010_evk-pinctrl.dtsi:107 */
			};

			/* node '/soc/iomuxc@401f8000/IOMUXC_GPIO_09_GPIOMUX_IO09' defined in modules/hal/nxp/dts/nxp/nxp_imx/rt/mimxrt1011dae5a-pinctrl.dtsi:189 */
			iomuxc_gpio_09_gpiomux_io09: IOMUXC_GPIO_09_GPIOMUX_IO09 {
				pinmux = < 0x401f8098 0x5 0x0 0x0 0x401f8148 >; /* in modules/hal/nxp/dts/nxp/nxp_imx/rt/mimxrt1011dae5a-pinctrl.dtsi:190 */
				phandle = < 0xe >;                              /* in zephyr/dts/arm/nxp/nxp_rt1010.dtsi:360 */
			};

			/* node '/soc/iomuxc@401f8000/IOMUXC_GPIO_09_LPUART1_RXD' defined in modules/hal/nxp/dts/nxp/nxp_imx/rt/mimxrt1011dae5a-pinctrl.dtsi:195 */
			iomuxc_gpio_09_lpuart1_rxd: IOMUXC_GPIO_09_LPUART1_RXD {
				pinmux = < 0x401f8098 0x0 0x401f81f0 0x1 0x401f8148 >; /* in modules/hal/nxp/dts/nxp/nxp_imx/rt/mimxrt1011dae5a-pinctrl.dtsi:196 */
				phandle = < 0x2b >;                                    /* in zephyr/boards/nxp/mimxrt1010_evk/mimxrt1010_evk-pinctrl.dtsi:49 */
			};

			/* node '/soc/iomuxc@401f8000/IOMUXC_GPIO_10_GPIOMUX_IO10' defined in modules/hal/nxp/dts/nxp/nxp_imx/rt/mimxrt1011dae5a-pinctrl.dtsi:210 */
			iomuxc_gpio_10_gpiomux_io10: IOMUXC_GPIO_10_GPIOMUX_IO10 {
				pinmux = < 0x401f8094 0x5 0x0 0x0 0x401f8144 >; /* in modules/hal/nxp/dts/nxp/nxp_imx/rt/mimxrt1011dae5a-pinctrl.dtsi:211 */
				phandle = < 0xf >;                              /* in zephyr/dts/arm/nxp/nxp_rt1010.dtsi:360 */
			};

			/* node '/soc/iomuxc@401f8000/IOMUXC_GPIO_10_LPUART1_TXD' defined in modules/hal/nxp/dts/nxp/nxp_imx/rt/mimxrt1011dae5a-pinctrl.dtsi:219 */
			iomuxc_gpio_10_lpuart1_txd: IOMUXC_GPIO_10_LPUART1_TXD {
				pinmux = < 0x401f8094 0x0 0x401f81f4 0x1 0x401f8144 >; /* in modules/hal/nxp/dts/nxp/nxp_imx/rt/mimxrt1011dae5a-pinctrl.dtsi:220 */
				phandle = < 0x2c >;                                    /* in zephyr/boards/nxp/mimxrt1010_evk/mimxrt1010_evk-pinctrl.dtsi:49 */
			};

			/* node '/soc/iomuxc@401f8000/IOMUXC_GPIO_11_GPIOMUX_IO11' defined in modules/hal/nxp/dts/nxp/nxp_imx/rt/mimxrt1011dae5a-pinctrl.dtsi:234 */
			iomuxc_gpio_11_gpiomux_io11: IOMUXC_GPIO_11_GPIOMUX_IO11 {
				pinmux = < 0x401f8090 0x5 0x0 0x0 0x401f8140 >; /* in modules/hal/nxp/dts/nxp/nxp_imx/rt/mimxrt1011dae5a-pinctrl.dtsi:235 */
				phandle = < 0x10 >;                             /* in zephyr/dts/arm/nxp/nxp_rt1010.dtsi:360 */
			};

			/* node '/soc/iomuxc@401f8000/IOMUXC_GPIO_12_GPIOMUX_IO12' defined in modules/hal/nxp/dts/nxp/nxp_imx/rt/mimxrt1011dae5a-pinctrl.dtsi:255 */
			iomuxc_gpio_12_gpiomux_io12: IOMUXC_GPIO_12_GPIOMUX_IO12 {
				pinmux = < 0x401f808c 0x5 0x0 0x0 0x401f813c >; /* in modules/hal/nxp/dts/nxp/nxp_imx/rt/mimxrt1011dae5a-pinctrl.dtsi:256 */
				phandle = < 0x11 >;                             /* in zephyr/dts/arm/nxp/nxp_rt1010.dtsi:360 */
			};

			/* node '/soc/iomuxc@401f8000/IOMUXC_GPIO_13_GPIOMUX_IO13' defined in modules/hal/nxp/dts/nxp/nxp_imx/rt/mimxrt1011dae5a-pinctrl.dtsi:279 */
			iomuxc_gpio_13_gpiomux_io13: IOMUXC_GPIO_13_GPIOMUX_IO13 {
				pinmux = < 0x401f8088 0x5 0x0 0x0 0x401f8138 >; /* in modules/hal/nxp/dts/nxp/nxp_imx/rt/mimxrt1011dae5a-pinctrl.dtsi:280 */
				phandle = < 0x12 >;                             /* in zephyr/dts/arm/nxp/nxp_rt1010.dtsi:360 */
			};

			/* node '/soc/iomuxc@401f8000/IOMUXC_GPIO_AD_00_GPIOMUX_IO14' defined in modules/hal/nxp/dts/nxp/nxp_imx/rt/mimxrt1011dae5a-pinctrl.dtsi:309 */
			iomuxc_gpio_ad_00_gpiomux_io14: IOMUXC_GPIO_AD_00_GPIOMUX_IO14 {
				pinmux = < 0x401f8048 0x5 0x0 0x0 0x401f80f8 >; /* in modules/hal/nxp/dts/nxp/nxp_imx/rt/mimxrt1011dae5a-pinctrl.dtsi:310 */
				phandle = < 0x13 >;                             /* in zephyr/dts/arm/nxp/nxp_rt1010.dtsi:360 */
			};

			/* node '/soc/iomuxc@401f8000/IOMUXC_GPIO_AD_01_ADC1_IN1' defined in modules/hal/nxp/dts/nxp/nxp_imx/rt/mimxrt1011dae5a-pinctrl.dtsi:324 */
			iomuxc_gpio_ad_01_adc1_in1: IOMUXC_GPIO_AD_01_ADC1_IN1 {
				pinmux = < 0x401f8044 0x5 0x0 0x0 0x401f80f4 >; /* in modules/hal/nxp/dts/nxp/nxp_imx/rt/mimxrt1011dae5a-pinctrl.dtsi:325 */
				phandle = < 0x23 >;                             /* in zephyr/boards/nxp/mimxrt1010_evk/mimxrt1010_evk-pinctrl.dtsi:15 */
			};

			/* node '/soc/iomuxc@401f8000/IOMUXC_GPIO_AD_01_GPIOMUX_IO15' defined in modules/hal/nxp/dts/nxp/nxp_imx/rt/mimxrt1011dae5a-pinctrl.dtsi:330 */
			iomuxc_gpio_ad_01_gpiomux_io15: IOMUXC_GPIO_AD_01_GPIOMUX_IO15 {
				pinmux = < 0x401f8044 0x5 0x0 0x0 0x401f80f4 >; /* in modules/hal/nxp/dts/nxp/nxp_imx/rt/mimxrt1011dae5a-pinctrl.dtsi:331 */
				phandle = < 0x14 >;                             /* in zephyr/dts/arm/nxp/nxp_rt1010.dtsi:360 */
			};

			/* node '/soc/iomuxc@401f8000/IOMUXC_GPIO_AD_01_LPUART4_RXD' defined in modules/hal/nxp/dts/nxp/nxp_imx/rt/mimxrt1011dae5a-pinctrl.dtsi:339 */
			iomuxc_gpio_ad_01_lpuart4_rxd: IOMUXC_GPIO_AD_01_LPUART4_RXD {
				pinmux = < 0x401f8044 0x0 0x401f8208 0x0 0x401f80f4 >; /* in modules/hal/nxp/dts/nxp/nxp_imx/rt/mimxrt1011dae5a-pinctrl.dtsi:340 */
				phandle = < 0x2d >;                                    /* in zephyr/boards/nxp/mimxrt1010_evk/mimxrt1010_evk-pinctrl.dtsi:78 */
			};

			/* node '/soc/iomuxc@401f8000/IOMUXC_GPIO_AD_02_ADC1_IN2' defined in modules/hal/nxp/dts/nxp/nxp_imx/rt/mimxrt1011dae5a-pinctrl.dtsi:351 */
			iomuxc_gpio_ad_02_adc1_in2: IOMUXC_GPIO_AD_02_ADC1_IN2 {
				pinmux = < 0x401f8040 0x5 0x0 0x0 0x401f80f0 >; /* in modules/hal/nxp/dts/nxp/nxp_imx/rt/mimxrt1011dae5a-pinctrl.dtsi:352 */
				phandle = < 0x24 >;                             /* in zephyr/boards/nxp/mimxrt1010_evk/mimxrt1010_evk-pinctrl.dtsi:15 */
			};

			/* node '/soc/iomuxc@401f8000/IOMUXC_GPIO_AD_02_GPIOMUX_IO16' defined in modules/hal/nxp/dts/nxp/nxp_imx/rt/mimxrt1011dae5a-pinctrl.dtsi:357 */
			iomuxc_gpio_ad_02_gpiomux_io16: IOMUXC_GPIO_AD_02_GPIOMUX_IO16 {
				pinmux = < 0x401f8040 0x5 0x0 0x0 0x401f80f0 >; /* in modules/hal/nxp/dts/nxp/nxp_imx/rt/mimxrt1011dae5a-pinctrl.dtsi:358 */
				phandle = < 0x15 >;                             /* in zephyr/dts/arm/nxp/nxp_rt1010.dtsi:360 */
			};

			/* node '/soc/iomuxc@401f8000/IOMUXC_GPIO_AD_02_LPUART4_TXD' defined in modules/hal/nxp/dts/nxp/nxp_imx/rt/mimxrt1011dae5a-pinctrl.dtsi:366 */
			iomuxc_gpio_ad_02_lpuart4_txd: IOMUXC_GPIO_AD_02_LPUART4_TXD {
				pinmux = < 0x401f8040 0x0 0x401f820c 0x0 0x401f80f0 >; /* in modules/hal/nxp/dts/nxp/nxp_imx/rt/mimxrt1011dae5a-pinctrl.dtsi:367 */
				phandle = < 0x2e >;                                    /* in zephyr/boards/nxp/mimxrt1010_evk/mimxrt1010_evk-pinctrl.dtsi:78 */
			};

			/* node '/soc/iomuxc@401f8000/IOMUXC_GPIO_AD_03_GPIOMUX_IO17' defined in modules/hal/nxp/dts/nxp/nxp_imx/rt/mimxrt1011dae5a-pinctrl.dtsi:381 */
			iomuxc_gpio_ad_03_gpiomux_io17: IOMUXC_GPIO_AD_03_GPIOMUX_IO17 {
				pinmux = < 0x401f803c 0x5 0x0 0x0 0x401f80ec >; /* in modules/hal/nxp/dts/nxp/nxp_imx/rt/mimxrt1011dae5a-pinctrl.dtsi:382 */
				phandle = < 0x16 >;                             /* in zephyr/dts/arm/nxp/nxp_rt1010.dtsi:360 */
			};

			/* node '/soc/iomuxc@401f8000/IOMUXC_GPIO_AD_03_LPSPI1_SDI' defined in modules/hal/nxp/dts/nxp/nxp_imx/rt/mimxrt1011dae5a-pinctrl.dtsi:393 */
			iomuxc_gpio_ad_03_lpspi1_sdi: IOMUXC_GPIO_AD_03_LPSPI1_SDI {
				pinmux = < 0x401f803c 0x0 0x401f81d8 0x0 0x401f80ec >; /* in modules/hal/nxp/dts/nxp/nxp_imx/rt/mimxrt1011dae5a-pinctrl.dtsi:394 */
				phandle = < 0x2a >;                                    /* in zephyr/boards/nxp/mimxrt1010_evk/mimxrt1010_evk-pinctrl.dtsi:36 */
			};

			/* node '/soc/iomuxc@401f8000/IOMUXC_GPIO_AD_04_GPIOMUX_IO18' defined in modules/hal/nxp/dts/nxp/nxp_imx/rt/mimxrt1011dae5a-pinctrl.dtsi:408 */
			iomuxc_gpio_ad_04_gpiomux_io18: IOMUXC_GPIO_AD_04_GPIOMUX_IO18 {
				pinmux = < 0x401f8038 0x5 0x0 0x0 0x401f80e8 >; /* in modules/hal/nxp/dts/nxp/nxp_imx/rt/mimxrt1011dae5a-pinctrl.dtsi:409 */
				phandle = < 0x17 >;                             /* in zephyr/dts/arm/nxp/nxp_rt1010.dtsi:360 */
			};

			/* node '/soc/iomuxc@401f8000/IOMUXC_GPIO_AD_04_LPSPI1_SDO' defined in modules/hal/nxp/dts/nxp/nxp_imx/rt/mimxrt1011dae5a-pinctrl.dtsi:417 */
			iomuxc_gpio_ad_04_lpspi1_sdo: IOMUXC_GPIO_AD_04_LPSPI1_SDO {
				pinmux = < 0x401f8038 0x0 0x401f81dc 0x0 0x401f80e8 >; /* in modules/hal/nxp/dts/nxp/nxp_imx/rt/mimxrt1011dae5a-pinctrl.dtsi:418 */
				phandle = < 0x29 >;                                    /* in zephyr/boards/nxp/mimxrt1010_evk/mimxrt1010_evk-pinctrl.dtsi:36 */
			};

			/* node '/soc/iomuxc@401f8000/IOMUXC_GPIO_AD_05_GPIOMUX_IO19' defined in modules/hal/nxp/dts/nxp/nxp_imx/rt/mimxrt1011dae5a-pinctrl.dtsi:432 */
			iomuxc_gpio_ad_05_gpiomux_io19: IOMUXC_GPIO_AD_05_GPIOMUX_IO19 {
				pinmux = < 0x401f8034 0x5 0x0 0x0 0x401f80e4 >; /* in modules/hal/nxp/dts/nxp/nxp_imx/rt/mimxrt1011dae5a-pinctrl.dtsi:433 */
				phandle = < 0x18 >;                             /* in zephyr/dts/arm/nxp/nxp_rt1010.dtsi:360 */
			};

			/* node '/soc/iomuxc@401f8000/IOMUXC_GPIO_AD_05_LPSPI1_PCS0' defined in modules/hal/nxp/dts/nxp/nxp_imx/rt/mimxrt1011dae5a-pinctrl.dtsi:441 */
			iomuxc_gpio_ad_05_lpspi1_pcs0: IOMUXC_GPIO_AD_05_LPSPI1_PCS0 {
				pinmux = < 0x401f8034 0x0 0x401f81d0 0x0 0x401f80e4 >; /* in modules/hal/nxp/dts/nxp/nxp_imx/rt/mimxrt1011dae5a-pinctrl.dtsi:442 */
				phandle = < 0x28 >;                                    /* in zephyr/boards/nxp/mimxrt1010_evk/mimxrt1010_evk-pinctrl.dtsi:36 */
			};

			/* node '/soc/iomuxc@401f8000/IOMUXC_GPIO_AD_06_GPIOMUX_IO20' defined in modules/hal/nxp/dts/nxp/nxp_imx/rt/mimxrt1011dae5a-pinctrl.dtsi:453 */
			iomuxc_gpio_ad_06_gpiomux_io20: IOMUXC_GPIO_AD_06_GPIOMUX_IO20 {
				pinmux = < 0x401f8030 0x5 0x0 0x0 0x401f80e0 >; /* in modules/hal/nxp/dts/nxp/nxp_imx/rt/mimxrt1011dae5a-pinctrl.dtsi:454 */
				phandle = < 0x19 >;                             /* in zephyr/dts/arm/nxp/nxp_rt1010.dtsi:360 */
			};

			/* node '/soc/iomuxc@401f8000/IOMUXC_GPIO_AD_06_LPSPI1_SCK' defined in modules/hal/nxp/dts/nxp/nxp_imx/rt/mimxrt1011dae5a-pinctrl.dtsi:465 */
			iomuxc_gpio_ad_06_lpspi1_sck: IOMUXC_GPIO_AD_06_LPSPI1_SCK {
				pinmux = < 0x401f8030 0x0 0x401f81d4 0x0 0x401f80e0 >; /* in modules/hal/nxp/dts/nxp/nxp_imx/rt/mimxrt1011dae5a-pinctrl.dtsi:466 */
				phandle = < 0x27 >;                                    /* in zephyr/boards/nxp/mimxrt1010_evk/mimxrt1010_evk-pinctrl.dtsi:36 */
			};

			/* node '/soc/iomuxc@401f8000/IOMUXC_GPIO_AD_07_GPIOMUX_IO21' defined in modules/hal/nxp/dts/nxp/nxp_imx/rt/mimxrt1011dae5a-pinctrl.dtsi:477 */
			iomuxc_gpio_ad_07_gpiomux_io21: IOMUXC_GPIO_AD_07_GPIOMUX_IO21 {
				pinmux = < 0x401f802c 0x5 0x0 0x0 0x401f80dc >; /* in modules/hal/nxp/dts/nxp/nxp_imx/rt/mimxrt1011dae5a-pinctrl.dtsi:478 */
				phandle = < 0x1a >;                             /* in zephyr/dts/arm/nxp/nxp_rt1010.dtsi:360 */
			};

			/* node '/soc/iomuxc@401f8000/IOMUXC_GPIO_AD_08_GPIOMUX_IO22' defined in modules/hal/nxp/dts/nxp/nxp_imx/rt/mimxrt1011dae5a-pinctrl.dtsi:512 */
			iomuxc_gpio_ad_08_gpiomux_io22: IOMUXC_GPIO_AD_08_GPIOMUX_IO22 {
				pinmux = < 0x401f8028 0x5 0x0 0x0 0x401f80d8 >; /* in modules/hal/nxp/dts/nxp/nxp_imx/rt/mimxrt1011dae5a-pinctrl.dtsi:513 */
				phandle = < 0x1b >;                             /* in zephyr/dts/arm/nxp/nxp_rt1010.dtsi:360 */
			};

			/* node '/soc/iomuxc@401f8000/IOMUXC_GPIO_AD_09_GPIOMUX_IO23' defined in modules/hal/nxp/dts/nxp/nxp_imx/rt/mimxrt1011dae5a-pinctrl.dtsi:542 */
			iomuxc_gpio_ad_09_gpiomux_io23: IOMUXC_GPIO_AD_09_GPIOMUX_IO23 {
				pinmux = < 0x401f8024 0x5 0x0 0x0 0x401f80d4 >; /* in modules/hal/nxp/dts/nxp/nxp_imx/rt/mimxrt1011dae5a-pinctrl.dtsi:543 */
				phandle = < 0x1c >;                             /* in zephyr/dts/arm/nxp/nxp_rt1010.dtsi:360 */
			};

			/* node '/soc/iomuxc@401f8000/IOMUXC_GPIO_AD_10_GPIOMUX_IO24' defined in modules/hal/nxp/dts/nxp/nxp_imx/rt/mimxrt1011dae5a-pinctrl.dtsi:563 */
			iomuxc_gpio_ad_10_gpiomux_io24: IOMUXC_GPIO_AD_10_GPIOMUX_IO24 {
				pinmux = < 0x401f8020 0x5 0x0 0x0 0x401f80d0 >; /* in modules/hal/nxp/dts/nxp/nxp_imx/rt/mimxrt1011dae5a-pinctrl.dtsi:564 */
				phandle = < 0x1d >;                             /* in zephyr/dts/arm/nxp/nxp_rt1010.dtsi:360 */
			};

			/* node '/soc/iomuxc@401f8000/IOMUXC_GPIO_AD_11_GPIOMUX_IO25' defined in modules/hal/nxp/dts/nxp/nxp_imx/rt/mimxrt1011dae5a-pinctrl.dtsi:590 */
			iomuxc_gpio_ad_11_gpiomux_io25: IOMUXC_GPIO_AD_11_GPIOMUX_IO25 {
				pinmux = < 0x401f801c 0x5 0x0 0x0 0x401f80cc >; /* in modules/hal/nxp/dts/nxp/nxp_imx/rt/mimxrt1011dae5a-pinctrl.dtsi:591 */
				phandle = < 0x1e >;                             /* in zephyr/dts/arm/nxp/nxp_rt1010.dtsi:360 */
			};

			/* node '/soc/iomuxc@401f8000/IOMUXC_GPIO_AD_12_GPIOMUX_IO26' defined in modules/hal/nxp/dts/nxp/nxp_imx/rt/mimxrt1011dae5a-pinctrl.dtsi:617 */
			iomuxc_gpio_ad_12_gpiomux_io26: IOMUXC_GPIO_AD_12_GPIOMUX_IO26 {
				pinmux = < 0x401f8018 0x5 0x0 0x0 0x401f80c8 >; /* in modules/hal/nxp/dts/nxp/nxp_imx/rt/mimxrt1011dae5a-pinctrl.dtsi:618 */
				phandle = < 0x1f >;                             /* in zephyr/dts/arm/nxp/nxp_rt1010.dtsi:360 */
			};

			/* node '/soc/iomuxc@401f8000/IOMUXC_GPIO_AD_13_GPIOMUX_IO27' defined in modules/hal/nxp/dts/nxp/nxp_imx/rt/mimxrt1011dae5a-pinctrl.dtsi:644 */
			iomuxc_gpio_ad_13_gpiomux_io27: IOMUXC_GPIO_AD_13_GPIOMUX_IO27 {
				pinmux = < 0x401f8014 0x5 0x0 0x0 0x401f80c4 >; /* in modules/hal/nxp/dts/nxp/nxp_imx/rt/mimxrt1011dae5a-pinctrl.dtsi:645 */
				phandle = < 0x20 >;                             /* in zephyr/dts/arm/nxp/nxp_rt1010.dtsi:360 */
			};

			/* node '/soc/iomuxc@401f8000/IOMUXC_GPIO_AD_14_GPIOMUX_IO28' defined in modules/hal/nxp/dts/nxp/nxp_imx/rt/mimxrt1011dae5a-pinctrl.dtsi:668 */
			iomuxc_gpio_ad_14_gpiomux_io28: IOMUXC_GPIO_AD_14_GPIOMUX_IO28 {
				pinmux = < 0x401f8010 0x5 0x0 0x0 0x401f80c0 >; /* in modules/hal/nxp/dts/nxp/nxp_imx/rt/mimxrt1011dae5a-pinctrl.dtsi:669 */
				phandle = < 0x21 >;                             /* in zephyr/dts/arm/nxp/nxp_rt1010.dtsi:360 */
			};

			/* node '/soc/iomuxc@401f8000/IOMUXC_GPIO_SD_00_GPIO2_IO00' defined in modules/hal/nxp/dts/nxp/nxp_imx/rt/mimxrt1011dae5a-pinctrl.dtsi:703 */
			iomuxc_gpio_sd_00_gpio2_io00: IOMUXC_GPIO_SD_00_GPIO2_IO00 {
				pinmux = < 0x401f8084 0x5 0x0 0x0 0x401f8134 >; /* in modules/hal/nxp/dts/nxp/nxp_imx/rt/mimxrt1011dae5a-pinctrl.dtsi:704 */
				phandle = < 0x3b >;                             /* in zephyr/dts/arm/nxp/nxp_rt1010.dtsi:79 */
			};

			/* node '/soc/iomuxc@401f8000/IOMUXC_GPIO_SD_01_GPIO2_IO01' defined in modules/hal/nxp/dts/nxp/nxp_imx/rt/mimxrt1011dae5a-pinctrl.dtsi:724 */
			iomuxc_gpio_sd_01_gpio2_io01: IOMUXC_GPIO_SD_01_GPIO2_IO01 {
				pinmux = < 0x401f8080 0x5 0x0 0x0 0x401f8130 >; /* in modules/hal/nxp/dts/nxp/nxp_imx/rt/mimxrt1011dae5a-pinctrl.dtsi:725 */
				phandle = < 0x3c >;                             /* in zephyr/dts/arm/nxp/nxp_rt1010.dtsi:79 */
			};

			/* node '/soc/iomuxc@401f8000/IOMUXC_GPIO_SD_02_GPIO2_IO02' defined in modules/hal/nxp/dts/nxp/nxp_imx/rt/mimxrt1011dae5a-pinctrl.dtsi:745 */
			iomuxc_gpio_sd_02_gpio2_io02: IOMUXC_GPIO_SD_02_GPIO2_IO02 {
				pinmux = < 0x401f807c 0x5 0x0 0x0 0x401f812c >; /* in modules/hal/nxp/dts/nxp/nxp_imx/rt/mimxrt1011dae5a-pinctrl.dtsi:746 */
				phandle = < 0x3d >;                             /* in zephyr/dts/arm/nxp/nxp_rt1010.dtsi:79 */
			};

			/* node '/soc/iomuxc@401f8000/IOMUXC_GPIO_SD_03_GPIO2_IO03' defined in modules/hal/nxp/dts/nxp/nxp_imx/rt/mimxrt1011dae5a-pinctrl.dtsi:766 */
			iomuxc_gpio_sd_03_gpio2_io03: IOMUXC_GPIO_SD_03_GPIO2_IO03 {
				pinmux = < 0x401f8078 0x5 0x0 0x0 0x401f8128 >; /* in modules/hal/nxp/dts/nxp/nxp_imx/rt/mimxrt1011dae5a-pinctrl.dtsi:767 */
				phandle = < 0x3e >;                             /* in zephyr/dts/arm/nxp/nxp_rt1010.dtsi:79 */
			};

			/* node '/soc/iomuxc@401f8000/IOMUXC_GPIO_SD_04_GPIO2_IO04' defined in modules/hal/nxp/dts/nxp/nxp_imx/rt/mimxrt1011dae5a-pinctrl.dtsi:787 */
			iomuxc_gpio_sd_04_gpio2_io04: IOMUXC_GPIO_SD_04_GPIO2_IO04 {
				pinmux = < 0x401f8074 0x5 0x0 0x0 0x401f8124 >; /* in modules/hal/nxp/dts/nxp/nxp_imx/rt/mimxrt1011dae5a-pinctrl.dtsi:788 */
				phandle = < 0x3f >;                             /* in zephyr/dts/arm/nxp/nxp_rt1010.dtsi:79 */
			};

			/* node '/soc/iomuxc@401f8000/IOMUXC_GPIO_SD_05_GPIO2_IO05' defined in modules/hal/nxp/dts/nxp/nxp_imx/rt/mimxrt1011dae5a-pinctrl.dtsi:802 */
			iomuxc_gpio_sd_05_gpio2_io05: IOMUXC_GPIO_SD_05_GPIO2_IO05 {
				pinmux = < 0x401f8070 0x5 0x0 0x0 0x401f8120 >; /* in modules/hal/nxp/dts/nxp/nxp_imx/rt/mimxrt1011dae5a-pinctrl.dtsi:803 */
				phandle = < 0x40 >;                             /* in zephyr/dts/arm/nxp/nxp_rt1010.dtsi:79 */
			};

			/* node '/soc/iomuxc@401f8000/IOMUXC_GPIO_SD_06_GPIO2_IO06' defined in modules/hal/nxp/dts/nxp/nxp_imx/rt/mimxrt1011dae5a-pinctrl.dtsi:817 */
			iomuxc_gpio_sd_06_gpio2_io06: IOMUXC_GPIO_SD_06_GPIO2_IO06 {
				pinmux = < 0x401f806c 0x5 0x0 0x0 0x401f811c >; /* in modules/hal/nxp/dts/nxp/nxp_imx/rt/mimxrt1011dae5a-pinctrl.dtsi:818 */
				phandle = < 0x41 >;                             /* in zephyr/dts/arm/nxp/nxp_rt1010.dtsi:79 */
			};

			/* node '/soc/iomuxc@401f8000/IOMUXC_GPIO_SD_07_GPIO2_IO07' defined in modules/hal/nxp/dts/nxp/nxp_imx/rt/mimxrt1011dae5a-pinctrl.dtsi:832 */
			iomuxc_gpio_sd_07_gpio2_io07: IOMUXC_GPIO_SD_07_GPIO2_IO07 {
				pinmux = < 0x401f8068 0x5 0x0 0x0 0x401f8118 >; /* in modules/hal/nxp/dts/nxp/nxp_imx/rt/mimxrt1011dae5a-pinctrl.dtsi:833 */
				phandle = < 0x42 >;                             /* in zephyr/dts/arm/nxp/nxp_rt1010.dtsi:79 */
			};

			/* node '/soc/iomuxc@401f8000/IOMUXC_GPIO_SD_08_GPIO2_IO08' defined in modules/hal/nxp/dts/nxp/nxp_imx/rt/mimxrt1011dae5a-pinctrl.dtsi:847 */
			iomuxc_gpio_sd_08_gpio2_io08: IOMUXC_GPIO_SD_08_GPIO2_IO08 {
				pinmux = < 0x401f8064 0x5 0x0 0x0 0x401f8114 >; /* in modules/hal/nxp/dts/nxp/nxp_imx/rt/mimxrt1011dae5a-pinctrl.dtsi:848 */
				phandle = < 0x43 >;                             /* in zephyr/dts/arm/nxp/nxp_rt1010.dtsi:79 */
			};

			/* node '/soc/iomuxc@401f8000/IOMUXC_GPIO_SD_09_GPIO2_IO09' defined in modules/hal/nxp/dts/nxp/nxp_imx/rt/mimxrt1011dae5a-pinctrl.dtsi:862 */
			iomuxc_gpio_sd_09_gpio2_io09: IOMUXC_GPIO_SD_09_GPIO2_IO09 {
				pinmux = < 0x401f8060 0x5 0x0 0x0 0x401f8110 >; /* in modules/hal/nxp/dts/nxp/nxp_imx/rt/mimxrt1011dae5a-pinctrl.dtsi:863 */
				phandle = < 0x44 >;                             /* in zephyr/dts/arm/nxp/nxp_rt1010.dtsi:79 */
			};

			/* node '/soc/iomuxc@401f8000/IOMUXC_GPIO_SD_10_GPIO2_IO10' defined in modules/hal/nxp/dts/nxp/nxp_imx/rt/mimxrt1011dae5a-pinctrl.dtsi:877 */
			iomuxc_gpio_sd_10_gpio2_io10: IOMUXC_GPIO_SD_10_GPIO2_IO10 {
				pinmux = < 0x401f805c 0x5 0x0 0x0 0x401f810c >; /* in modules/hal/nxp/dts/nxp/nxp_imx/rt/mimxrt1011dae5a-pinctrl.dtsi:878 */
				phandle = < 0x45 >;                             /* in zephyr/dts/arm/nxp/nxp_rt1010.dtsi:79 */
			};

			/* node '/soc/iomuxc@401f8000/IOMUXC_GPIO_SD_11_GPIO2_IO11' defined in modules/hal/nxp/dts/nxp/nxp_imx/rt/mimxrt1011dae5a-pinctrl.dtsi:892 */
			iomuxc_gpio_sd_11_gpio2_io11: IOMUXC_GPIO_SD_11_GPIO2_IO11 {
				pinmux = < 0x401f8058 0x5 0x0 0x0 0x401f8108 >; /* in modules/hal/nxp/dts/nxp/nxp_imx/rt/mimxrt1011dae5a-pinctrl.dtsi:893 */
				phandle = < 0x46 >;                             /* in zephyr/dts/arm/nxp/nxp_rt1010.dtsi:79 */
			};

			/* node '/soc/iomuxc@401f8000/IOMUXC_GPIO_SD_12_GPIO2_IO12' defined in modules/hal/nxp/dts/nxp/nxp_imx/rt/mimxrt1011dae5a-pinctrl.dtsi:910 */
			iomuxc_gpio_sd_12_gpio2_io12: IOMUXC_GPIO_SD_12_GPIO2_IO12 {
				pinmux = < 0x401f8054 0x5 0x0 0x0 0x401f8104 >; /* in modules/hal/nxp/dts/nxp/nxp_imx/rt/mimxrt1011dae5a-pinctrl.dtsi:911 */
				phandle = < 0x47 >;                             /* in zephyr/dts/arm/nxp/nxp_rt1010.dtsi:79 */
			};

			/* node '/soc/iomuxc@401f8000/IOMUXC_GPIO_SD_13_GPIO2_IO13' defined in modules/hal/nxp/dts/nxp/nxp_imx/rt/mimxrt1011dae5a-pinctrl.dtsi:934 */
			iomuxc_gpio_sd_13_gpio2_io13: IOMUXC_GPIO_SD_13_GPIO2_IO13 {
				pinmux = < 0x401f8050 0x5 0x0 0x0 0x401f8100 >; /* in modules/hal/nxp/dts/nxp/nxp_imx/rt/mimxrt1011dae5a-pinctrl.dtsi:935 */
				phandle = < 0x48 >;                             /* in zephyr/dts/arm/nxp/nxp_rt1010.dtsi:79 */
			};

			/* node '/soc/iomuxc@401f8000/IOMUXC_SNVS_PMIC_ON_REQ_GPIO5_IO00' defined in modules/hal/nxp/dts/nxp/nxp_imx/rt/mimxrt1011dae5a-pinctrl.dtsi:946 */
			iomuxc_snvs_pmic_on_req_gpio5_io00: IOMUXC_SNVS_PMIC_ON_REQ_GPIO5_IO00 {
				pinmux = < 0x400a8000 0x5 0x0 0x0 0x400a8010 >; /* in modules/hal/nxp/dts/nxp/nxp_imx/rt/mimxrt1011dae5a-pinctrl.dtsi:947 */
				phandle = < 0x22 >;                             /* in zephyr/dts/arm/nxp/nxp_rt1010.dtsi:392 */
			};
		};

		/* node '/soc/uart@40184000' defined in zephyr/dts/arm/nxp/nxp_rt10xx.dtsi:540 */
		lpuart1: arduino_serial: uart@40184000 {
			compatible = "nxp,lpuart";             /* in zephyr/dts/arm/nxp/nxp_rt10xx.dtsi:541 */
			reg = < 0x40184000 0x4000 >;           /* in zephyr/dts/arm/nxp/nxp_rt10xx.dtsi:542 */
			interrupts = < 0x14 0x0 >;             /* in zephyr/dts/arm/nxp/nxp_rt10xx.dtsi:543 */
			clocks = < &ccm 0x300 0x7c 0x18 >;     /* in zephyr/dts/arm/nxp/nxp_rt10xx.dtsi:544 */
			dmas = < &edma0 0x1 0x2 >,
			       < &edma0 0x2 0x3 >;             /* in zephyr/dts/arm/nxp/nxp_rt10xx.dtsi:545 */
			dma-names = "tx",
			            "rx";                      /* in zephyr/dts/arm/nxp/nxp_rt10xx.dtsi:546 */
			status = "okay";                       /* in zephyr/boards/nxp/mimxrt1010_evk/mimxrt1010_evk.dts:148 */
			current-speed = < 0x1c200 >;           /* in zephyr/boards/nxp/mimxrt1010_evk/mimxrt1010_evk.dts:149 */
			pinctrl-0 = < &pinmux_lpuart1 >;       /* in zephyr/boards/nxp/mimxrt1010_evk/mimxrt1010_evk.dts:150 */
			pinctrl-1 = < &pinmux_lpuart1_sleep >; /* in zephyr/boards/nxp/mimxrt1010_evk/mimxrt1010_evk.dts:151 */
			pinctrl-names = "default",
			                "sleep";               /* in zephyr/boards/nxp/mimxrt1010_evk/mimxrt1010_evk.dts:152 */
		};

		/* node '/soc/uart@40188000' defined in zephyr/dts/arm/nxp/nxp_rt10xx.dtsi:550 */
		lpuart2: uart@40188000 {
			compatible = "nxp,lpuart";         /* in zephyr/dts/arm/nxp/nxp_rt10xx.dtsi:551 */
			reg = < 0x40188000 0x4000 >;       /* in zephyr/dts/arm/nxp/nxp_rt10xx.dtsi:552 */
			interrupts = < 0x15 0x0 >;         /* in zephyr/dts/arm/nxp/nxp_rt10xx.dtsi:553 */
			clocks = < &ccm 0x300 0x68 0x1c >; /* in zephyr/dts/arm/nxp/nxp_rt10xx.dtsi:554 */
			dmas = < &edma0 0x3 0x42 >,
			       < &edma0 0x4 0x43 >;        /* in zephyr/dts/arm/nxp/nxp_rt10xx.dtsi:555 */
			dma-names = "tx",
			            "rx";                  /* in zephyr/dts/arm/nxp/nxp_rt10xx.dtsi:556 */
			status = "disabled";               /* in zephyr/dts/arm/nxp/nxp_rt10xx.dtsi:557 */
		};

		/* node '/soc/uart@4018c000' defined in zephyr/dts/arm/nxp/nxp_rt10xx.dtsi:560 */
		lpuart3: uart@4018c000 {
			compatible = "nxp,lpuart";        /* in zephyr/dts/arm/nxp/nxp_rt10xx.dtsi:561 */
			reg = < 0x4018c000 0x4000 >;      /* in zephyr/dts/arm/nxp/nxp_rt10xx.dtsi:562 */
			interrupts = < 0x16 0x0 >;        /* in zephyr/dts/arm/nxp/nxp_rt10xx.dtsi:563 */
			clocks = < &ccm 0x300 0x68 0xc >; /* in zephyr/dts/arm/nxp/nxp_rt10xx.dtsi:564 */
			dmas = < &edma0 0x5 0x4 >,
			       < &edma0 0x6 0x5 >;        /* in zephyr/dts/arm/nxp/nxp_rt10xx.dtsi:565 */
			dma-names = "tx",
			            "rx";                 /* in zephyr/dts/arm/nxp/nxp_rt10xx.dtsi:566 */
			status = "disabled";              /* in zephyr/dts/arm/nxp/nxp_rt10xx.dtsi:567 */
		};

		/* node '/soc/uart@40190000' defined in zephyr/dts/arm/nxp/nxp_rt10xx.dtsi:570 */
		lpuart4: uart@40190000 {
			compatible = "nxp,lpuart";             /* in zephyr/dts/arm/nxp/nxp_rt10xx.dtsi:571 */
			reg = < 0x40190000 0x4000 >;           /* in zephyr/dts/arm/nxp/nxp_rt10xx.dtsi:572 */
			interrupts = < 0x17 0x0 >;             /* in zephyr/dts/arm/nxp/nxp_rt10xx.dtsi:573 */
			clocks = < &ccm 0x300 0x6c 0x18 >;     /* in zephyr/dts/arm/nxp/nxp_rt10xx.dtsi:574 */
			dmas = < &edma0 0x7 0x44 >,
			       < &edma0 0x8 0x45 >;            /* in zephyr/dts/arm/nxp/nxp_rt10xx.dtsi:575 */
			dma-names = "tx",
			            "rx";                      /* in zephyr/dts/arm/nxp/nxp_rt10xx.dtsi:576 */
			status = "disabled";                   /* in zephyr/dts/arm/nxp/nxp_rt10xx.dtsi:577 */
			pinctrl-0 = < &pinmux_lpuart4 >;       /* in zephyr/boards/nxp/mimxrt1010_evk/mimxrt1010_evk.dts:90 */
			pinctrl-1 = < &pinmux_lpuart4_sleep >; /* in zephyr/boards/nxp/mimxrt1010_evk/mimxrt1010_evk.dts:91 */
			pinctrl-names = "default",
			                "sleep";               /* in zephyr/boards/nxp/mimxrt1010_evk/mimxrt1010_evk.dts:92 */
		};

		/* node '/soc/adc@400c4000' defined in zephyr/dts/arm/nxp/nxp_rt10xx.dtsi:620 */
		adc1: adc@400c4000 {
			compatible = "nxp,mcux-12b1msps-sar"; /* in zephyr/dts/arm/nxp/nxp_rt10xx.dtsi:621 */
			reg = < 0x400c4000 0x1000 >;          /* in zephyr/dts/arm/nxp/nxp_rt10xx.dtsi:622 */
			interrupts = < 0x43 0x0 >;            /* in zephyr/dts/arm/nxp/nxp_rt10xx.dtsi:623 */
			clk-divider = < 0x1 >;                /* in zephyr/dts/arm/nxp/nxp_rt10xx.dtsi:624 */
			sample-period-mode = < 0x0 >;         /* in zephyr/dts/arm/nxp/nxp_rt10xx.dtsi:625 */
			#io-channel-cells = < 0x1 >;          /* in zephyr/dts/arm/nxp/nxp_rt10xx.dtsi:627 */
			status = "okay";                      /* in zephyr/boards/nxp/mimxrt1010_evk/mimxrt1010_evk.dts:169 */
			pinctrl-0 = < &pinmux_adc1 >;         /* in zephyr/boards/nxp/mimxrt1010_evk/mimxrt1010_evk.dts:170 */
			pinctrl-names = "default";            /* in zephyr/boards/nxp/mimxrt1010_evk/mimxrt1010_evk.dts:171 */
		};

		/* node '/soc/adc@400c8000' defined in zephyr/dts/arm/nxp/nxp_rt10xx.dtsi:630 */
		adc2: adc@400c8000 {
			compatible = "nxp,mcux-12b1msps-sar"; /* in zephyr/dts/arm/nxp/nxp_rt10xx.dtsi:631 */
			reg = < 0x400c8000 0x1000 >;          /* in zephyr/dts/arm/nxp/nxp_rt10xx.dtsi:632 */
			interrupts = < 0x44 0x0 >;            /* in zephyr/dts/arm/nxp/nxp_rt10xx.dtsi:633 */
			clk-divider = < 0x1 >;                /* in zephyr/dts/arm/nxp/nxp_rt10xx.dtsi:634 */
			sample-period-mode = < 0x0 >;         /* in zephyr/dts/arm/nxp/nxp_rt10xx.dtsi:635 */
			status = "disabled";                  /* in zephyr/dts/arm/nxp/nxp_rt10xx.dtsi:636 */
			#io-channel-cells = < 0x1 >;          /* in zephyr/dts/arm/nxp/nxp_rt10xx.dtsi:637 */
		};

		/* node '/soc/reset-controller@400f8000' defined in zephyr/dts/arm/nxp/nxp_rt10xx.dtsi:853 */
		src: reset-controller@400f8000 {
			compatible = "nxp,imx-src";  /* in zephyr/dts/arm/nxp/nxp_rt10xx.dtsi:854 */
			reg = < 0x400f8000 0x4000 >; /* in zephyr/dts/arm/nxp/nxp_rt10xx.dtsi:855 */
			status = "okay";             /* in zephyr/dts/arm/nxp/nxp_rt10xx.dtsi:856 */
		};

		/* node '/soc/random@400cc000' defined in zephyr/dts/arm/nxp/nxp_rt10xx.dtsi:859 */
		trng: random@400cc000 {
			compatible = "nxp,kinetis-trng"; /* in zephyr/dts/arm/nxp/nxp_rt10xx.dtsi:860 */
			reg = < 0x400cc000 0x4000 >;     /* in zephyr/dts/arm/nxp/nxp_rt10xx.dtsi:861 */
			status = "okay";                 /* in zephyr/dts/arm/nxp/nxp_rt10xx.dtsi:862 */
			interrupts = < 0x35 0x0 >;       /* in zephyr/dts/arm/nxp/nxp_rt10xx.dtsi:863 */
		};

		/* node '/soc/usbh@402e0000' defined in zephyr/dts/arm/nxp/nxp_rt10xx.dtsi:886 */
		usbh1: usbh@402e0000 {
			compatible = "nxp,uhc-ehci"; /* in zephyr/dts/arm/nxp/nxp_rt10xx.dtsi:887 */
			reg = < 0x402e0000 0x200 >;  /* in zephyr/dts/arm/nxp/nxp_rt10xx.dtsi:888 */
			interrupts = < 0x71 0x1 >;   /* in zephyr/dts/arm/nxp/nxp_rt10xx.dtsi:889 */
			interrupt-names = "usb_otg"; /* in zephyr/dts/arm/nxp/nxp_rt10xx.dtsi:890 */
			clocks = < &usbclk >;        /* in zephyr/dts/arm/nxp/nxp_rt10xx.dtsi:891 */
			status = "disabled";         /* in zephyr/dts/arm/nxp/nxp_rt10xx.dtsi:892 */
		};

		/* node '/soc/usbh@402e0200' defined in zephyr/dts/arm/nxp/nxp_rt10xx.dtsi:895 */
		usbh2: usbh@402e0200 {
			compatible = "nxp,uhc-ehci"; /* in zephyr/dts/arm/nxp/nxp_rt10xx.dtsi:896 */
			reg = < 0x402e0200 0x200 >;  /* in zephyr/dts/arm/nxp/nxp_rt10xx.dtsi:897 */
			interrupts = < 0x70 0x1 >;   /* in zephyr/dts/arm/nxp/nxp_rt10xx.dtsi:898 */
			interrupt-names = "usb_otg"; /* in zephyr/dts/arm/nxp/nxp_rt10xx.dtsi:899 */
			clocks = < &usbclk >;        /* in zephyr/dts/arm/nxp/nxp_rt10xx.dtsi:900 */
			status = "disabled";         /* in zephyr/dts/arm/nxp/nxp_rt10xx.dtsi:901 */
		};

		/* node '/soc/usbphy@400d9000' defined in zephyr/dts/arm/nxp/nxp_rt10xx.dtsi:904 */
		usbphy1: usbphy@400d9000 {
			compatible = "nxp,usbphy";   /* in zephyr/dts/arm/nxp/nxp_rt10xx.dtsi:905 */
			reg = < 0x400d9000 0x1000 >; /* in zephyr/dts/arm/nxp/nxp_rt10xx.dtsi:906 */
			status = "disabled";         /* in zephyr/dts/arm/nxp/nxp_rt10xx.dtsi:907 */
		};

		/* node '/soc/usbphy@400da000' defined in zephyr/dts/arm/nxp/nxp_rt10xx.dtsi:910 */
		usbphy2: usbphy@400da000 {
			compatible = "nxp,usbphy";   /* in zephyr/dts/arm/nxp/nxp_rt10xx.dtsi:911 */
			reg = < 0x400da000 0x1000 >; /* in zephyr/dts/arm/nxp/nxp_rt10xx.dtsi:912 */
			status = "disabled";         /* in zephyr/dts/arm/nxp/nxp_rt10xx.dtsi:913 */
		};

		/* node '/soc/dma-controller@400e8000' defined in zephyr/dts/arm/nxp/nxp_rt10xx.dtsi:947 */
		edma0: dma-controller@400e8000 {
			#dma-cells = < 0x2 >;              /* in zephyr/dts/arm/nxp/nxp_rt10xx.dtsi:948 */
			compatible = "nxp,mcux-edma";      /* in zephyr/dts/arm/nxp/nxp_rt10xx.dtsi:949 */
			nxp,version = < 0x2 >;             /* in zephyr/dts/arm/nxp/nxp_rt10xx.dtsi:950 */
			dma-requests = < 0x80 >;           /* in zephyr/dts/arm/nxp/nxp_rt10xx.dtsi:952 */
			nxp,mem2mem;                       /* in zephyr/dts/arm/nxp/nxp_rt10xx.dtsi:953 */
			nxp,a-on;                          /* in zephyr/dts/arm/nxp/nxp_rt10xx.dtsi:954 */
			reg = < 0x400e8000 0x4000 >,
			      < 0x400ec000 0x4000 >;       /* in zephyr/dts/arm/nxp/nxp_rt10xx.dtsi:955 */
			interrupts = < 0x0 0x0 >,
			             < 0x1 0x0 >,
			             < 0x2 0x0 >,
			             < 0x3 0x0 >,
			             < 0x4 0x0 >,
			             < 0x5 0x0 >,
			             < 0x6 0x0 >,
			             < 0x7 0x0 >,
			             < 0x8 0x0 >,
			             < 0x9 0x0 >,
			             < 0xa 0x0 >,
			             < 0xb 0x0 >,
			             < 0xc 0x0 >,
			             < 0xd 0x0 >,
			             < 0xe 0x0 >,
			             < 0xf 0x0 >;          /* in zephyr/dts/arm/nxp/nxp_rt10xx.dtsi:957 */
			clocks = < &ccm 0x700 0x7c 0xc0 >; /* in zephyr/dts/arm/nxp/nxp_rt10xx.dtsi:962 */
			irq-shared-offset = < 0x0 >;       /* in zephyr/dts/arm/nxp/nxp_rt1010.dtsi:56 */
			dma-channels = < 0x10 >;           /* in zephyr/dts/arm/nxp/nxp_rt1010.dtsi:57 */
			status = "okay";                   /* in zephyr/boards/nxp/mimxrt1010_evk/mimxrt1010_evk.dts:180 */
			phandle = < 0x34 >;                /* in zephyr/dts/arm/nxp/nxp_rt10xx.dtsi:545 */
		};

		/* node '/soc/wdog@400b8000' defined in zephyr/dts/arm/nxp/nxp_rt10xx.dtsi:996 */
		wdog0: wdog@400b8000 {
			compatible = "nxp,imx-wdog"; /* in zephyr/dts/arm/nxp/nxp_rt10xx.dtsi:997 */
			reg = < 0x400b8000 0xa >;    /* in zephyr/dts/arm/nxp/nxp_rt10xx.dtsi:998 */
			status = "disabled";         /* in zephyr/dts/arm/nxp/nxp_rt10xx.dtsi:999 */
			interrupts = < 0x5c 0x0 >;   /* in zephyr/dts/arm/nxp/nxp_rt10xx.dtsi:1000 */
		};

		/* node '/soc/anatop@400d8000' defined in zephyr/dts/arm/nxp/nxp_rt10xx.dtsi:1010 */
		anatop: anatop@400d8000 {
			compatible = "nxp,imx-anatop"; /* in zephyr/dts/arm/nxp/nxp_rt10xx.dtsi:1011 */
			reg = < 0x400d8000 0x4000 >;   /* in zephyr/dts/arm/nxp/nxp_rt10xx.dtsi:1012 */
			#clock-cells = < 0x4 >;        /* in zephyr/dts/arm/nxp/nxp_rt10xx.dtsi:1013 */
			#pll-clock-cells = < 0x3 >;    /* in zephyr/dts/arm/nxp/nxp_rt10xx.dtsi:1014 */
			phandle = < 0x4b >;            /* in zephyr/dts/arm/nxp/nxp_rt1010.dtsi:296 */
		};

		/* node '/soc/iomuxcgpr@400ac000' defined in zephyr/dts/arm/nxp/nxp_rt10xx.dtsi:1017 */
		iomuxcgpr: iomuxcgpr@400ac000 {
			compatible = "nxp,imx-gpr";  /* in zephyr/dts/arm/nxp/nxp_rt10xx.dtsi:1018 */
			reg = < 0x400ac000 0x4000 >; /* in zephyr/dts/arm/nxp/nxp_rt10xx.dtsi:1019 */
			#pinmux-cells = < 0x2 >;     /* in zephyr/dts/arm/nxp/nxp_rt10xx.dtsi:1020 */
			phandle = < 0x4c >;          /* in zephyr/dts/arm/nxp/nxp_rt1010.dtsi:310 */
		};

		/* node '/soc/pxp@402b4000' defined in zephyr/dts/arm/nxp/nxp_rt10xx.dtsi:1023 */
		pxp: pxp@402b4000 {
			compatible = "nxp,pxp";      /* in zephyr/dts/arm/nxp/nxp_rt10xx.dtsi:1024 */
			reg = < 0x402b4000 0x4000 >; /* in zephyr/dts/arm/nxp/nxp_rt10xx.dtsi:1025 */
			interrupts = < 0x2c 0x0 >;   /* in zephyr/dts/arm/nxp/nxp_rt10xx.dtsi:1026 */
			status = "disabled";         /* in zephyr/dts/arm/nxp/nxp_rt10xx.dtsi:1027 */
			#dma-cells = < 0x0 >;        /* in zephyr/dts/arm/nxp/nxp_rt10xx.dtsi:1028 */
		};

		/* node '/soc/qdec@403c8000' defined in zephyr/dts/arm/nxp/nxp_rt10xx.dtsi:1125 */
		qdec1: qdec@403c8000 {
			compatible = "nxp,mcux-qdec"; /* in zephyr/dts/arm/nxp/nxp_rt10xx.dtsi:1126 */
			reg = < 0x403c8000 0x4000 >;  /* in zephyr/dts/arm/nxp/nxp_rt10xx.dtsi:1127 */
			interrupts = < 0x81 0x0 >;    /* in zephyr/dts/arm/nxp/nxp_rt10xx.dtsi:1128 */
			status = "disabled";          /* in zephyr/dts/arm/nxp/nxp_rt10xx.dtsi:1129 */
		};

		/* node '/soc/qdec@403cc000' defined in zephyr/dts/arm/nxp/nxp_rt10xx.dtsi:1132 */
		qdec2: qdec@403cc000 {
			compatible = "nxp,mcux-qdec"; /* in zephyr/dts/arm/nxp/nxp_rt10xx.dtsi:1133 */
			reg = < 0x403cc000 0x4000 >;  /* in zephyr/dts/arm/nxp/nxp_rt10xx.dtsi:1134 */
			interrupts = < 0x82 0x0 >;    /* in zephyr/dts/arm/nxp/nxp_rt10xx.dtsi:1135 */
			status = "disabled";          /* in zephyr/dts/arm/nxp/nxp_rt10xx.dtsi:1136 */
		};

		/* node '/soc/qdec@403d0000' defined in zephyr/dts/arm/nxp/nxp_rt10xx.dtsi:1139 */
		qdec3: qdec@403d0000 {
			compatible = "nxp,mcux-qdec"; /* in zephyr/dts/arm/nxp/nxp_rt10xx.dtsi:1140 */
			reg = < 0x403d0000 0x4000 >;  /* in zephyr/dts/arm/nxp/nxp_rt10xx.dtsi:1141 */
			interrupts = < 0x83 0x0 >;    /* in zephyr/dts/arm/nxp/nxp_rt10xx.dtsi:1142 */
			status = "disabled";          /* in zephyr/dts/arm/nxp/nxp_rt10xx.dtsi:1143 */
		};

		/* node '/soc/qdec@403d4000' defined in zephyr/dts/arm/nxp/nxp_rt10xx.dtsi:1146 */
		qdec4: qdec@403d4000 {
			compatible = "nxp,mcux-qdec"; /* in zephyr/dts/arm/nxp/nxp_rt10xx.dtsi:1147 */
			reg = < 0x403d4000 0x4000 >;  /* in zephyr/dts/arm/nxp/nxp_rt10xx.dtsi:1148 */
			interrupts = < 0x84 0x0 >;    /* in zephyr/dts/arm/nxp/nxp_rt10xx.dtsi:1149 */
			status = "disabled";          /* in zephyr/dts/arm/nxp/nxp_rt10xx.dtsi:1150 */
		};

		/* node '/soc/xbar1@403bc000' defined in zephyr/dts/arm/nxp/nxp_rt10xx.dtsi:1153 */
		xbar1: xbar1@403bc000 {
			compatible = "nxp,mcux-xbar"; /* in zephyr/dts/arm/nxp/nxp_rt10xx.dtsi:1154 */
			reg = < 0x403bc000 0x4000 >;  /* in zephyr/dts/arm/nxp/nxp_rt10xx.dtsi:1155 */
			interrupts = < 0x74 0x0 >,
			             < 0x75 0x0 >;    /* in zephyr/dts/arm/nxp/nxp_rt10xx.dtsi:1156 */
			status = "disabled";          /* in zephyr/dts/arm/nxp/nxp_rt10xx.dtsi:1157 */
		};

		/* node '/soc/xbar2@403c0000' defined in zephyr/dts/arm/nxp/nxp_rt10xx.dtsi:1160 */
		xbar2: xbar2@403c0000 {
			compatible = "nxp,mcux-xbar"; /* in zephyr/dts/arm/nxp/nxp_rt10xx.dtsi:1161 */
			reg = < 0x403c0000 0x4000 >;  /* in zephyr/dts/arm/nxp/nxp_rt10xx.dtsi:1162 */
			status = "disabled";          /* in zephyr/dts/arm/nxp/nxp_rt10xx.dtsi:1163 */
		};

		/* node '/soc/xbar3@403c4000' defined in zephyr/dts/arm/nxp/nxp_rt10xx.dtsi:1166 */
		xbar3: xbar3@403c4000 {
			compatible = "nxp,mcux-xbar"; /* in zephyr/dts/arm/nxp/nxp_rt10xx.dtsi:1167 */
			reg = < 0x403c4000 0x4000 >;  /* in zephyr/dts/arm/nxp/nxp_rt10xx.dtsi:1168 */
			status = "disabled";          /* in zephyr/dts/arm/nxp/nxp_rt10xx.dtsi:1169 */
		};

		/* node '/soc/dcp@402fc000' defined in zephyr/dts/arm/nxp/nxp_rt10xx.dtsi:1172 */
		dcp: dcp@402fc000 {
			compatible = "nxp,mcux-dcp"; /* in zephyr/dts/arm/nxp/nxp_rt10xx.dtsi:1173 */
			reg = < 0x402fc000 0x4000 >; /* in zephyr/dts/arm/nxp/nxp_rt10xx.dtsi:1174 */
			interrupts = < 0x32 0x0 >,
			             < 0x33 0x0 >;   /* in zephyr/dts/arm/nxp/nxp_rt10xx.dtsi:1175 */
			status = "okay";             /* in zephyr/dts/arm/nxp/nxp_rt10xx.dtsi:1176 */
		};

		/* node '/soc/tempmon@400d8000' defined in zephyr/dts/arm/nxp/nxp_rt10xx.dtsi:1179 */
		tempmon: tempmon@400d8000 {
			compatible = "nxp,tempmon"; /* in zephyr/dts/arm/nxp/nxp_rt10xx.dtsi:1180 */
			reg = < 0x400d8000 0x2a0 >; /* in zephyr/dts/arm/nxp/nxp_rt10xx.dtsi:1181 */
			status = "disabled";        /* in zephyr/dts/arm/nxp/nxp_rt10xx.dtsi:1182 */
		};

		/* node '/soc/pit@40084000' defined in zephyr/dts/arm/nxp/nxp_rt10xx.dtsi:1185 */
		pit0: pit@40084000 {
			compatible = "nxp,pit";           /* in zephyr/dts/arm/nxp/nxp_rt10xx.dtsi:1186 */
			reg = < 0x40084000 0x1000 >;      /* in zephyr/dts/arm/nxp/nxp_rt10xx.dtsi:1187 */
			clocks = < &ccm 0x1000 0x0 0x0 >; /* in zephyr/dts/arm/nxp/nxp_rt10xx.dtsi:1188 */
			max-load-value = < 0xffffffff >;  /* in zephyr/dts/arm/nxp/nxp_rt10xx.dtsi:1190 */
			#address-cells = < 0x1 >;         /* in zephyr/dts/arm/nxp/nxp_rt10xx.dtsi:1192 */
			#size-cells = < 0x0 >;            /* in zephyr/dts/arm/nxp/nxp_rt10xx.dtsi:1193 */
			interrupts = < 0x18 0x0 >;        /* in zephyr/dts/arm/nxp/nxp_rt1010.dtsi:396 */
			status = "okay";                  /* in zephyr/boards/nxp/mimxrt1010_evk/mimxrt1010_evk.dts:196 */

			/* node '/soc/pit@40084000/pit0_channel@0' defined in zephyr/dts/arm/nxp/nxp_rt10xx.dtsi:1195 */
			pit0_channel0: pit0_channel@0 {
				compatible = "nxp,pit-channel"; /* in zephyr/dts/arm/nxp/nxp_rt10xx.dtsi:1196 */
				reg = < 0x0 >;                  /* in zephyr/dts/arm/nxp/nxp_rt10xx.dtsi:1197 */
				status = "disabled";            /* in zephyr/dts/arm/nxp/nxp_rt10xx.dtsi:1198 */
			};

			/* node '/soc/pit@40084000/pit0_channel@1' defined in zephyr/dts/arm/nxp/nxp_rt10xx.dtsi:1201 */
			pit0_channel1: pit0_channel@1 {
				compatible = "nxp,pit-channel"; /* in zephyr/dts/arm/nxp/nxp_rt10xx.dtsi:1202 */
				reg = < 0x1 >;                  /* in zephyr/dts/arm/nxp/nxp_rt10xx.dtsi:1203 */
				status = "disabled";            /* in zephyr/dts/arm/nxp/nxp_rt10xx.dtsi:1204 */
			};

			/* node '/soc/pit@40084000/pit0_channel@2' defined in zephyr/dts/arm/nxp/nxp_rt10xx.dtsi:1207 */
			pit0_channel2: pit0_channel@2 {
				compatible = "nxp,pit-channel"; /* in zephyr/dts/arm/nxp/nxp_rt10xx.dtsi:1208 */
				reg = < 0x2 >;                  /* in zephyr/dts/arm/nxp/nxp_rt10xx.dtsi:1209 */
				status = "disabled";            /* in zephyr/dts/arm/nxp/nxp_rt10xx.dtsi:1210 */
			};

			/* node '/soc/pit@40084000/pit0_channel@3' defined in zephyr/dts/arm/nxp/nxp_rt10xx.dtsi:1213 */
			pit0_channel3: pit0_channel@3 {
				compatible = "nxp,pit-channel"; /* in zephyr/dts/arm/nxp/nxp_rt10xx.dtsi:1214 */
				reg = < 0x3 >;                  /* in zephyr/dts/arm/nxp/nxp_rt10xx.dtsi:1215 */
				status = "disabled";            /* in zephyr/dts/arm/nxp/nxp_rt10xx.dtsi:1216 */
			};
		};

		/* node '/soc/flexio@401ac000' defined in zephyr/dts/arm/nxp/nxp_rt10xx.dtsi:1220 */
		flexio1: flexio@401ac000 {
			compatible = "nxp,flexio";        /* in zephyr/dts/arm/nxp/nxp_rt10xx.dtsi:1221 */
			reg = < 0x401ac000 0x4000 >;      /* in zephyr/dts/arm/nxp/nxp_rt10xx.dtsi:1222 */
			status = "disabled";              /* in zephyr/dts/arm/nxp/nxp_rt10xx.dtsi:1223 */
			interrupts = < 0x5a 0x0 >;        /* in zephyr/dts/arm/nxp/nxp_rt10xx.dtsi:1224 */
			clocks = < &ccm 0x1100 0x0 0x0 >; /* in zephyr/dts/arm/nxp/nxp_rt10xx.dtsi:1225 */
		};

		/* node '/soc/gpio@42000000' defined in zephyr/dts/arm/nxp/nxp_rt1010.dtsi:73 */
		gpio2: gpio@42000000 {
			compatible = "nxp,imx-gpio";                /* in zephyr/dts/arm/nxp/nxp_rt1010.dtsi:74 */
			reg = < 0x42000000 0x4000 >;                /* in zephyr/dts/arm/nxp/nxp_rt1010.dtsi:75 */
			interrupts = < 0x48 0x0 >;                  /* in zephyr/dts/arm/nxp/nxp_rt1010.dtsi:76 */
			gpio-controller;                            /* in zephyr/dts/arm/nxp/nxp_rt1010.dtsi:77 */
			#gpio-cells = < 0x2 >;                      /* in zephyr/dts/arm/nxp/nxp_rt1010.dtsi:78 */
			pinmux = < &iomuxc_gpio_sd_00_gpio2_io00 >,
			         < &iomuxc_gpio_sd_01_gpio2_io01 >,
			         < &iomuxc_gpio_sd_02_gpio2_io02 >,
			         < &iomuxc_gpio_sd_03_gpio2_io03 >,
			         < &iomuxc_gpio_sd_04_gpio2_io04 >,
			         < &iomuxc_gpio_sd_05_gpio2_io05 >,
			         < &iomuxc_gpio_sd_06_gpio2_io06 >,
			         < &iomuxc_gpio_sd_07_gpio2_io07 >,
			         < &iomuxc_gpio_sd_08_gpio2_io08 >,
			         < &iomuxc_gpio_sd_09_gpio2_io09 >,
			         < &iomuxc_gpio_sd_10_gpio2_io10 >,
			         < &iomuxc_gpio_sd_11_gpio2_io11 >,
			         < &iomuxc_gpio_sd_12_gpio2_io12 >,
			         < &iomuxc_gpio_sd_13_gpio2_io13 >; /* in zephyr/dts/arm/nxp/nxp_rt1010.dtsi:79 */
			phandle = < 0x52 >;                         /* in zephyr/boards/nxp/mimxrt1010_evk/mimxrt1010_evk.dts:52 */
		};

		/* node '/soc/spi@400a0000' defined in zephyr/dts/arm/nxp/nxp_rt1010.dtsi:104 */
		flexspi: spi@400a0000 {
			compatible = "nxp,imx-flexspi";  /* in zephyr/dts/arm/nxp/nxp_rt1010.dtsi:105 */
			interrupts = < 0x1a 0x0 >;       /* in zephyr/dts/arm/nxp/nxp_rt1010.dtsi:107 */
			#address-cells = < 0x1 >;        /* in zephyr/dts/arm/nxp/nxp_rt1010.dtsi:108 */
			#size-cells = < 0x0 >;           /* in zephyr/dts/arm/nxp/nxp_rt1010.dtsi:109 */
			ahb-bufferable;                  /* in zephyr/dts/arm/nxp/nxp_rt1010.dtsi:110 */
			ahb-cacheable;                   /* in zephyr/dts/arm/nxp/nxp_rt1010.dtsi:111 */
			clocks = < &ccm 0xf00 0x0 0x0 >; /* in zephyr/dts/arm/nxp/nxp_rt1010.dtsi:113 */
			status = "okay";                 /* in zephyr/boards/nxp/mimxrt1010_evk/mimxrt1010_evk.dts:96 */
			reg = < 0x400a0000 0x4000 >,
			      < 0x60000000 0x1000000 >;  /* in zephyr/boards/nxp/mimxrt1010_evk/mimxrt1010_evk.dts:97 */

			/* node '/soc/spi@400a0000/at25sf128a@0' defined in zephyr/boards/nxp/mimxrt1010_evk/mimxrt1010_evk.dts:99 */
			at25sf128a: at25sf128a@0 {
				compatible = "nxp,imx-flexspi-nor"; /* in zephyr/boards/nxp/mimxrt1010_evk/mimxrt1010_evk.dts:100 */
				size = < 0x8000000 >;               /* in zephyr/boards/nxp/mimxrt1010_evk/mimxrt1010_evk.dts:101 */
				reg = < 0x0 >;                      /* in zephyr/boards/nxp/mimxrt1010_evk/mimxrt1010_evk.dts:102 */
				spi-max-frequency = < 0x7ed6b40 >;  /* in zephyr/boards/nxp/mimxrt1010_evk/mimxrt1010_evk.dts:103 */
				status = "okay";                    /* in zephyr/boards/nxp/mimxrt1010_evk/mimxrt1010_evk.dts:104 */
				jedec-id = [ 1F 89 01 ];            /* in zephyr/boards/nxp/mimxrt1010_evk/mimxrt1010_evk.dts:105 */
				erase-block-size = < 0x1000 >;      /* in zephyr/boards/nxp/mimxrt1010_evk/mimxrt1010_evk.dts:106 */
				write-block-size = < 0x1 >;         /* in zephyr/boards/nxp/mimxrt1010_evk/mimxrt1010_evk.dts:107 */

				/* node '/soc/spi@400a0000/at25sf128a@0/partitions' defined in zephyr/boards/nxp/mimxrt1010_evk/mimxrt1010_evk.dts:109 */
				partitions {
					compatible = "fixed-partitions"; /* in zephyr/boards/nxp/mimxrt1010_evk/mimxrt1010_evk.dts:110 */
					#address-cells = < 0x1 >;        /* in zephyr/boards/nxp/mimxrt1010_evk/mimxrt1010_evk.dts:111 */
					#size-cells = < 0x1 >;           /* in zephyr/boards/nxp/mimxrt1010_evk/mimxrt1010_evk.dts:112 */

					/* node '/soc/spi@400a0000/at25sf128a@0/partitions/partition@0' defined in zephyr/boards/nxp/mimxrt1010_evk/mimxrt1010_evk.dts:118 */
					boot_partition: partition@0 {
						label = "mcuboot";     /* in zephyr/boards/nxp/mimxrt1010_evk/mimxrt1010_evk.dts:119 */
						reg = < 0x0 0x20000 >; /* in zephyr/boards/nxp/mimxrt1010_evk/mimxrt1010_evk.dts:120 */
					};

					/* node '/soc/spi@400a0000/at25sf128a@0/partitions/partition@20000' defined in zephyr/boards/nxp/mimxrt1010_evk/mimxrt1010_evk.dts:123 */
					slot0_partition: partition@20000 {
						label = "image-0";          /* in zephyr/boards/nxp/mimxrt1010_evk/mimxrt1010_evk.dts:124 */
						reg = < 0x20000 0x700000 >; /* in zephyr/boards/nxp/mimxrt1010_evk/mimxrt1010_evk.dts:125 */
					};

					/* node '/soc/spi@400a0000/at25sf128a@0/partitions/partition@720000' defined in zephyr/boards/nxp/mimxrt1010_evk/mimxrt1010_evk.dts:128 */
					slot1_partition: partition@720000 {
						label = "image-1";           /* in zephyr/boards/nxp/mimxrt1010_evk/mimxrt1010_evk.dts:129 */
						reg = < 0x720000 0x700000 >; /* in zephyr/boards/nxp/mimxrt1010_evk/mimxrt1010_evk.dts:130 */
					};

					/* node '/soc/spi@400a0000/at25sf128a@0/partitions/partition@E20000' defined in zephyr/boards/nxp/mimxrt1010_evk/mimxrt1010_evk.dts:133 */
					storage_partition: partition@E20000 {
						label = "storage";           /* in zephyr/boards/nxp/mimxrt1010_evk/mimxrt1010_evk.dts:134 */
						reg = < 0xe20000 0x1e0000 >; /* in zephyr/boards/nxp/mimxrt1010_evk/mimxrt1010_evk.dts:135 */
					};
				};
			};
		};

		/* node '/soc/i2c@401a4000' defined in zephyr/dts/arm/nxp/nxp_rt1010.dtsi:123 */
		lpi2c1: arduino_i2c: i2c@401a4000 {
			compatible = "nxp,lpi2c";         /* in zephyr/dts/arm/nxp/nxp_rt1010.dtsi:124 */
			clock-frequency = < 0x186a0 >;    /* in zephyr/dts/arm/nxp/nxp_rt1010.dtsi:125 */
			#address-cells = < 0x1 >;         /* in zephyr/dts/arm/nxp/nxp_rt1010.dtsi:126 */
			#size-cells = < 0x0 >;            /* in zephyr/dts/arm/nxp/nxp_rt1010.dtsi:127 */
			reg = < 0x401a4000 0x4000 >;      /* in zephyr/dts/arm/nxp/nxp_rt1010.dtsi:128 */
			interrupts = < 0x1c 0x0 >;        /* in zephyr/dts/arm/nxp/nxp_rt1010.dtsi:129 */
			clocks = < &ccm 0x400 0x70 0x6 >; /* in zephyr/dts/arm/nxp/nxp_rt1010.dtsi:130 */
			status = "okay";                  /* in zephyr/boards/nxp/mimxrt1010_evk/mimxrt1010_evk.dts:142 */
			pinctrl-0 = < &pinmux_lpi2c1 >;   /* in zephyr/boards/nxp/mimxrt1010_evk/mimxrt1010_evk.dts:143 */
			pinctrl-names = "default";        /* in zephyr/boards/nxp/mimxrt1010_evk/mimxrt1010_evk.dts:144 */
		};

		/* node '/soc/i2c@401a8000' defined in zephyr/dts/arm/nxp/nxp_rt1010.dtsi:134 */
		lpi2c2: i2c@401a8000 {
			compatible = "nxp,lpi2c";         /* in zephyr/dts/arm/nxp/nxp_rt1010.dtsi:135 */
			clock-frequency = < 0x186a0 >;    /* in zephyr/dts/arm/nxp/nxp_rt1010.dtsi:136 */
			#address-cells = < 0x1 >;         /* in zephyr/dts/arm/nxp/nxp_rt1010.dtsi:137 */
			#size-cells = < 0x0 >;            /* in zephyr/dts/arm/nxp/nxp_rt1010.dtsi:138 */
			reg = < 0x401a8000 0x4000 >;      /* in zephyr/dts/arm/nxp/nxp_rt1010.dtsi:139 */
			interrupts = < 0x1d 0x0 >;        /* in zephyr/dts/arm/nxp/nxp_rt1010.dtsi:140 */
			clocks = < &ccm 0x400 0x70 0x8 >; /* in zephyr/dts/arm/nxp/nxp_rt1010.dtsi:141 */
			status = "disabled";              /* in zephyr/dts/arm/nxp/nxp_rt1010.dtsi:142 */
		};

		/* node '/soc/spi@40194000' defined in zephyr/dts/arm/nxp/nxp_rt1010.dtsi:156 */
		lpspi1: arduino_spi: spi@40194000 {
			compatible = "nxp,lpspi";         /* in zephyr/dts/arm/nxp/nxp_rt1010.dtsi:157 */
			reg = < 0x40194000 0x4000 >;      /* in zephyr/dts/arm/nxp/nxp_rt1010.dtsi:158 */
			interrupts = < 0x20 0x3 >;        /* in zephyr/dts/arm/nxp/nxp_rt1010.dtsi:159 */
			clocks = < &ccm 0x500 0x6c 0x0 >; /* in zephyr/dts/arm/nxp/nxp_rt1010.dtsi:161 */
			#address-cells = < 0x1 >;         /* in zephyr/dts/arm/nxp/nxp_rt1010.dtsi:162 */
			#size-cells = < 0x0 >;            /* in zephyr/dts/arm/nxp/nxp_rt1010.dtsi:163 */
			tx-fifo-size = < 0x10 >;          /* in zephyr/dts/arm/nxp/nxp_rt1010.dtsi:164 */
			rx-fifo-size = < 0x10 >;          /* in zephyr/dts/arm/nxp/nxp_rt1010.dtsi:165 */
			status = "okay";                  /* in zephyr/boards/nxp/mimxrt1010_evk/mimxrt1010_evk.dts:156 */
			dmas = < &edma0 0x0 0xd >,
			       < &edma0 0x1 0xe >;        /* in zephyr/boards/nxp/mimxrt1010_evk/mimxrt1010_evk.dts:158 */
			dma-names = "rx",
			            "tx";                 /* in zephyr/boards/nxp/mimxrt1010_evk/mimxrt1010_evk.dts:159 */
			pinctrl-0 = < &pinmux_lpspi1 >;   /* in zephyr/boards/nxp/mimxrt1010_evk/mimxrt1010_evk.dts:160 */
			pinctrl-names = "default";        /* in zephyr/boards/nxp/mimxrt1010_evk/mimxrt1010_evk.dts:161 */
		};

		/* node '/soc/spi@40198000' defined in zephyr/dts/arm/nxp/nxp_rt1010.dtsi:168 */
		lpspi2: spi@40198000 {
			compatible = "nxp,lpspi";         /* in zephyr/dts/arm/nxp/nxp_rt1010.dtsi:169 */
			reg = < 0x40198000 0x4000 >;      /* in zephyr/dts/arm/nxp/nxp_rt1010.dtsi:170 */
			interrupts = < 0x21 0x3 >;        /* in zephyr/dts/arm/nxp/nxp_rt1010.dtsi:171 */
			status = "disabled";              /* in zephyr/dts/arm/nxp/nxp_rt1010.dtsi:172 */
			clocks = < &ccm 0x500 0x6c 0x2 >; /* in zephyr/dts/arm/nxp/nxp_rt1010.dtsi:173 */
			#address-cells = < 0x1 >;         /* in zephyr/dts/arm/nxp/nxp_rt1010.dtsi:174 */
			#size-cells = < 0x0 >;            /* in zephyr/dts/arm/nxp/nxp_rt1010.dtsi:175 */
			tx-fifo-size = < 0x10 >;          /* in zephyr/dts/arm/nxp/nxp_rt1010.dtsi:176 */
			rx-fifo-size = < 0x10 >;          /* in zephyr/dts/arm/nxp/nxp_rt1010.dtsi:177 */
		};

		/* node '/soc/flexpwm@401cc000' defined in zephyr/dts/arm/nxp/nxp_rt1010.dtsi:195 */
		flexpwm1: flexpwm@401cc000 {
			compatible = "nxp,flexpwm";  /* in zephyr/dts/arm/nxp/nxp_rt1010.dtsi:196 */
			reg = < 0x401cc000 0x4000 >; /* in zephyr/dts/arm/nxp/nxp_rt1010.dtsi:197 */
			interrupts = < 0x26 0x0 >;   /* in zephyr/dts/arm/nxp/nxp_rt1010.dtsi:198 */

			/* node '/soc/flexpwm@401cc000/pwm0' defined in zephyr/dts/arm/nxp/nxp_rt1010.dtsi:200 */
			flexpwm1_pwm0: pwm0 {
				compatible = "nxp,imx-pwm";      /* in zephyr/dts/arm/nxp/nxp_rt1010.dtsi:201 */
				index = < 0x0 >;                 /* in zephyr/dts/arm/nxp/nxp_rt1010.dtsi:202 */
				interrupts = < 0x22 0x0 >;       /* in zephyr/dts/arm/nxp/nxp_rt1010.dtsi:203 */
				#pwm-cells = < 0x3 >;            /* in zephyr/dts/arm/nxp/nxp_rt1010.dtsi:204 */
				clocks = < &ccm 0xc00 0x0 0x0 >; /* in zephyr/dts/arm/nxp/nxp_rt1010.dtsi:205 */
				nxp,prescaler = < 0x80 >;        /* in zephyr/dts/arm/nxp/nxp_rt1010.dtsi:206 */
				status = "disabled";             /* in zephyr/dts/arm/nxp/nxp_rt1010.dtsi:207 */
			};

			/* node '/soc/flexpwm@401cc000/pwm1' defined in zephyr/dts/arm/nxp/nxp_rt1010.dtsi:210 */
			flexpwm1_pwm1: pwm1 {
				compatible = "nxp,imx-pwm";      /* in zephyr/dts/arm/nxp/nxp_rt1010.dtsi:211 */
				index = < 0x1 >;                 /* in zephyr/dts/arm/nxp/nxp_rt1010.dtsi:212 */
				interrupts = < 0x23 0x0 >;       /* in zephyr/dts/arm/nxp/nxp_rt1010.dtsi:213 */
				#pwm-cells = < 0x3 >;            /* in zephyr/dts/arm/nxp/nxp_rt1010.dtsi:214 */
				clocks = < &ccm 0xc00 0x0 0x0 >; /* in zephyr/dts/arm/nxp/nxp_rt1010.dtsi:215 */
				nxp,prescaler = < 0x80 >;        /* in zephyr/dts/arm/nxp/nxp_rt1010.dtsi:216 */
				status = "disabled";             /* in zephyr/dts/arm/nxp/nxp_rt1010.dtsi:217 */
			};

			/* node '/soc/flexpwm@401cc000/pwm2' defined in zephyr/dts/arm/nxp/nxp_rt1010.dtsi:220 */
			flexpwm1_pwm2: pwm2 {
				compatible = "nxp,imx-pwm";      /* in zephyr/dts/arm/nxp/nxp_rt1010.dtsi:221 */
				index = < 0x2 >;                 /* in zephyr/dts/arm/nxp/nxp_rt1010.dtsi:222 */
				interrupts = < 0x24 0x0 >;       /* in zephyr/dts/arm/nxp/nxp_rt1010.dtsi:223 */
				#pwm-cells = < 0x3 >;            /* in zephyr/dts/arm/nxp/nxp_rt1010.dtsi:224 */
				clocks = < &ccm 0xc00 0x0 0x0 >; /* in zephyr/dts/arm/nxp/nxp_rt1010.dtsi:225 */
				nxp,prescaler = < 0x80 >;        /* in zephyr/dts/arm/nxp/nxp_rt1010.dtsi:226 */
				status = "disabled";             /* in zephyr/dts/arm/nxp/nxp_rt1010.dtsi:227 */
			};

			/* node '/soc/flexpwm@401cc000/pwm3' defined in zephyr/dts/arm/nxp/nxp_rt1010.dtsi:230 */
			flexpwm1_pwm3: pwm3 {
				compatible = "nxp,imx-pwm";      /* in zephyr/dts/arm/nxp/nxp_rt1010.dtsi:231 */
				index = < 0x3 >;                 /* in zephyr/dts/arm/nxp/nxp_rt1010.dtsi:232 */
				interrupts = < 0x25 0x0 >;       /* in zephyr/dts/arm/nxp/nxp_rt1010.dtsi:233 */
				#pwm-cells = < 0x3 >;            /* in zephyr/dts/arm/nxp/nxp_rt1010.dtsi:234 */
				clocks = < &ccm 0xc00 0x0 0x0 >; /* in zephyr/dts/arm/nxp/nxp_rt1010.dtsi:235 */
				nxp,prescaler = < 0x80 >;        /* in zephyr/dts/arm/nxp/nxp_rt1010.dtsi:236 */
				status = "disabled";             /* in zephyr/dts/arm/nxp/nxp_rt1010.dtsi:237 */
			};
		};

		/* node '/soc/usbd@400e4000' defined in zephyr/dts/arm/nxp/nxp_rt1010.dtsi:251 */
		usb1: zephyr_udc0: usbd@400e4000 {
			compatible = "nxp,ehci";       /* in zephyr/dts/arm/nxp/nxp_rt1010.dtsi:252 */
			reg = < 0x400e4000 0x200 >;    /* in zephyr/dts/arm/nxp/nxp_rt1010.dtsi:253 */
			interrupts = < 0x19 0x1 >;     /* in zephyr/dts/arm/nxp/nxp_rt1010.dtsi:254 */
			interrupt-names = "usb_otg";   /* in zephyr/dts/arm/nxp/nxp_rt1010.dtsi:255 */
			clocks = < &usbclk >;          /* in zephyr/dts/arm/nxp/nxp_rt1010.dtsi:256 */
			num-bidir-endpoints = < 0x8 >; /* in zephyr/dts/arm/nxp/nxp_rt1010.dtsi:257 */
			status = "okay";               /* in zephyr/boards/nxp/mimxrt1010_evk/mimxrt1010_evk.dts:165 */
		};

		/* node '/soc/sai@401e0000' defined in zephyr/dts/arm/nxp/nxp_rt1010.dtsi:283 */
		sai1: sai@401e0000 {
			compatible = "nxp,mcux-i2s";                   /* in zephyr/dts/arm/nxp/nxp_rt1010.dtsi:284 */
			#address-cells = < 0x1 >;                      /* in zephyr/dts/arm/nxp/nxp_rt1010.dtsi:285 */
			#size-cells = < 0x0 >;                         /* in zephyr/dts/arm/nxp/nxp_rt1010.dtsi:286 */
			#pinmux-cells = < 0x2 >;                       /* in zephyr/dts/arm/nxp/nxp_rt1010.dtsi:287 */
			reg = < 0x401e0000 0x4000 >;                   /* in zephyr/dts/arm/nxp/nxp_rt1010.dtsi:288 */
			clocks = < &ccm 0xb00 0x7c 0x12 >;             /* in zephyr/dts/arm/nxp/nxp_rt1010.dtsi:289 */
			clock-mux = < 0x2 >;                           /* in zephyr/dts/arm/nxp/nxp_rt1010.dtsi:291 */
			pll-clocks = < &anatop 0x70 0xc000 0x0 >,
			             < &anatop 0x70 0x7f 0x20 >,
			             < &anatop 0x70 0x180000 0x1 >,
			             < &anatop 0x80 0x3fffffff 0x4d >,
			             < &anatop 0x90 0x3fffffff 0x64 >; /* in zephyr/dts/arm/nxp/nxp_rt1010.dtsi:296 */
			pll-clock-names = "src",
			                  "lp",
			                  "pd",
			                  "num",
			                  "den";                       /* in zephyr/dts/arm/nxp/nxp_rt1010.dtsi:301 */
			pre-div = < 0x3 >;                             /* in zephyr/dts/arm/nxp/nxp_rt1010.dtsi:308 */
			podf = < 0xf >;                                /* in zephyr/dts/arm/nxp/nxp_rt1010.dtsi:309 */
			pinmuxes = < &iomuxcgpr 0x4 0x80000 >;         /* in zephyr/dts/arm/nxp/nxp_rt1010.dtsi:310 */
			interrupts = < 0x38 0x0 >;                     /* in zephyr/dts/arm/nxp/nxp_rt1010.dtsi:311 */
			dmas = < &edma0 0x0 0x13 >,
			       < &edma0 0x0 0x14 >;                    /* in zephyr/dts/arm/nxp/nxp_rt1010.dtsi:312 */
			dma-names = "rx",
			            "tx";                              /* in zephyr/dts/arm/nxp/nxp_rt1010.dtsi:313 */
			nxp,tx-channel = < 0x1 >;                      /* in zephyr/dts/arm/nxp/nxp_rt1010.dtsi:317 */
			nxp,tx-dma-channel = < 0x0 >;                  /* in zephyr/dts/arm/nxp/nxp_rt1010.dtsi:318 */
			nxp,rx-dma-channel = < 0x1 >;                  /* in zephyr/dts/arm/nxp/nxp_rt1010.dtsi:319 */
			status = "disabled";                           /* in zephyr/dts/arm/nxp/nxp_rt1010.dtsi:320 */
			pinctrl-0 = < &pinmux_sai1 >;                  /* in zephyr/boards/nxp/mimxrt1010_evk/mimxrt1010_evk.dts:175 */
			pinctrl-names = "default";                     /* in zephyr/boards/nxp/mimxrt1010_evk/mimxrt1010_evk.dts:176 */
		};

		/* node '/soc/sai@401e8000' defined in zephyr/dts/arm/nxp/nxp_rt1010.dtsi:323 */
		sai3: sai@401e8000 {
			compatible = "nxp,mcux-i2s";                   /* in zephyr/dts/arm/nxp/nxp_rt1010.dtsi:324 */
			#address-cells = < 0x1 >;                      /* in zephyr/dts/arm/nxp/nxp_rt1010.dtsi:325 */
			#size-cells = < 0x0 >;                         /* in zephyr/dts/arm/nxp/nxp_rt1010.dtsi:326 */
			#pinmux-cells = < 0x2 >;                       /* in zephyr/dts/arm/nxp/nxp_rt1010.dtsi:327 */
			reg = < 0x401e8000 0x4000 >;                   /* in zephyr/dts/arm/nxp/nxp_rt1010.dtsi:328 */
			clocks = < &ccm 0xb02 0x7c 0x16 >;             /* in zephyr/dts/arm/nxp/nxp_rt1010.dtsi:329 */
			clock-mux = < 0x2 >;                           /* in zephyr/dts/arm/nxp/nxp_rt1010.dtsi:331 */
			pre-div = < 0x0 >;                             /* in zephyr/dts/arm/nxp/nxp_rt1010.dtsi:332 */
			podf = < 0x3f >;                               /* in zephyr/dts/arm/nxp/nxp_rt1010.dtsi:333 */
			pll-clocks = < &anatop 0x70 0xc000 0x0 >,
			             < &anatop 0x70 0x7f 0x20 >,
			             < &anatop 0x70 0x180000 0x1 >,
			             < &anatop 0x80 0x3fffffff 0x4d >,
			             < &anatop 0x90 0x3fffffff 0x64 >; /* in zephyr/dts/arm/nxp/nxp_rt1010.dtsi:334 */
			pll-clock-names = "src",
			                  "lp",
			                  "pd",
			                  "num",
			                  "den";                       /* in zephyr/dts/arm/nxp/nxp_rt1010.dtsi:339 */
			pinmuxes = < &iomuxcgpr 0x4 0x200000 >;        /* in zephyr/dts/arm/nxp/nxp_rt1010.dtsi:340 */
			interrupts = < 0x3a 0x0 >,
			             < 0x3b 0x0 >;                     /* in zephyr/dts/arm/nxp/nxp_rt1010.dtsi:341 */
			dmas = < &edma0 0x0 0x53 >,
			       < &edma0 0x0 0x54 >;                    /* in zephyr/dts/arm/nxp/nxp_rt1010.dtsi:342 */
			dma-names = "rx",
			            "tx";                              /* in zephyr/dts/arm/nxp/nxp_rt1010.dtsi:343 */
			nxp,tx-channel = < 0x0 >;                      /* in zephyr/dts/arm/nxp/nxp_rt1010.dtsi:344 */
			nxp,tx-dma-channel = < 0x5 >;                  /* in zephyr/dts/arm/nxp/nxp_rt1010.dtsi:345 */
			nxp,rx-dma-channel = < 0x6 >;                  /* in zephyr/dts/arm/nxp/nxp_rt1010.dtsi:346 */
			status = "disabled";                           /* in zephyr/dts/arm/nxp/nxp_rt1010.dtsi:347 */
		};
	};

	/* node '/cpus' defined in zephyr/dts/arm/nxp/nxp_rt10xx.dtsi:26 */
	cpus {
		#address-cells = < 0x1 >; /* in zephyr/dts/arm/nxp/nxp_rt10xx.dtsi:27 */
		#size-cells = < 0x0 >;    /* in zephyr/dts/arm/nxp/nxp_rt10xx.dtsi:28 */

		/* node '/cpus/cpu@0' defined in zephyr/dts/arm/nxp/nxp_rt10xx.dtsi:30 */
		cpu0: cpu@0 {
			device_type = "cpu";                        /* in zephyr/dts/arm/nxp/nxp_rt10xx.dtsi:31 */
			compatible = "arm,cortex-m7";               /* in zephyr/dts/arm/nxp/nxp_rt10xx.dtsi:32 */
			d-cache-line-size = < 0x20 >;               /* in zephyr/dts/arm/nxp/nxp_rt10xx.dtsi:33 */
			reg = < 0x0 >;                              /* in zephyr/dts/arm/nxp/nxp_rt10xx.dtsi:34 */
			cpu-power-states = < &idle &suspend &off >; /* in zephyr/dts/arm/nxp/nxp_rt10xx.dtsi:35 */
			#address-cells = < 0x1 >;                   /* in zephyr/dts/arm/nxp/nxp_rt10xx.dtsi:36 */
			#size-cells = < 0x1 >;                      /* in zephyr/dts/arm/nxp/nxp_rt10xx.dtsi:37 */

			/* node '/cpus/cpu@0/mpu@e000ed90' defined in zephyr/dts/arm/nxp/nxp_rt10xx.dtsi:39 */
			mpu: mpu@e000ed90 {
				compatible = "arm,armv7m-mpu"; /* in zephyr/dts/arm/nxp/nxp_rt10xx.dtsi:40 */
				reg = < 0xe000ed90 0x40 >;     /* in zephyr/dts/arm/nxp/nxp_rt10xx.dtsi:41 */
			};

			/* node '/cpus/cpu@0/itm@e0000000' defined in zephyr/dts/arm/nxp/nxp_rt10xx.dtsi:44 */
			itm: itm@e0000000 {
				compatible = "arm,armv7m-itm";     /* in zephyr/dts/arm/nxp/nxp_rt10xx.dtsi:45 */
				reg = < 0xe0000000 0x1000 >;       /* in zephyr/dts/arm/nxp/nxp_rt10xx.dtsi:46 */
				swo-ref-frequency = < 0x7de2900 >; /* in zephyr/dts/arm/nxp/nxp_rt10xx.dtsi:47 */
			};
		};

		/* node '/cpus/power-states' defined in zephyr/dts/arm/nxp/nxp_rt10xx.dtsi:51 */
		power-states {

			/* node '/cpus/power-states/idle' defined in zephyr/dts/arm/nxp/nxp_rt10xx.dtsi:52 */
			idle: idle {
				compatible = "zephyr,power-state"; /* in zephyr/dts/arm/nxp/nxp_rt10xx.dtsi:53 */
				power-state-name = "runtime-idle"; /* in zephyr/dts/arm/nxp/nxp_rt10xx.dtsi:54 */
				exit-latency-us = < 0xfa0 >;       /* in zephyr/dts/arm/nxp/nxp_rt10xx.dtsi:55 */
				min-residency-us = < 0x1388 >;     /* in zephyr/dts/arm/nxp/nxp_rt10xx.dtsi:56 */
				phandle = < 0x4e >;                /* in zephyr/dts/arm/nxp/nxp_rt10xx.dtsi:35 */
			};

			/* node '/cpus/power-states/suspend' defined in zephyr/dts/arm/nxp/nxp_rt10xx.dtsi:59 */
			suspend: suspend {
				compatible = "zephyr,power-state";    /* in zephyr/dts/arm/nxp/nxp_rt10xx.dtsi:60 */
				power-state-name = "suspend-to-idle"; /* in zephyr/dts/arm/nxp/nxp_rt10xx.dtsi:61 */
				exit-latency-us = < 0x1388 >;         /* in zephyr/dts/arm/nxp/nxp_rt10xx.dtsi:62 */
				min-residency-us = < 0x2710 >;        /* in zephyr/dts/arm/nxp/nxp_rt10xx.dtsi:63 */
				phandle = < 0x4f >;                   /* in zephyr/dts/arm/nxp/nxp_rt10xx.dtsi:35 */
			};

			/* node '/cpus/power-states/off' defined in zephyr/dts/arm/nxp/nxp_rt10xx.dtsi:66 */
			off: off {
				status = "disabled";               /* in zephyr/dts/arm/nxp/nxp_rt10xx.dtsi:68 */
				compatible = "zephyr,power-state"; /* in zephyr/dts/arm/nxp/nxp_rt10xx.dtsi:69 */
				power-state-name = "soft-off";     /* in zephyr/dts/arm/nxp/nxp_rt10xx.dtsi:70 */
				phandle = < 0x50 >;                /* in zephyr/dts/arm/nxp/nxp_rt10xx.dtsi:35 */
			};
		};
	};

	/* node '/system-clock' defined in zephyr/dts/arm/nxp/nxp_rt10xx.dtsi:75 */
	sysclk: system-clock {
		compatible = "fixed-clock";       /* in zephyr/dts/arm/nxp/nxp_rt10xx.dtsi:76 */
		#clock-cells = < 0x0 >;           /* in zephyr/dts/arm/nxp/nxp_rt10xx.dtsi:78 */
		clock-frequency = < 0x1dcd6500 >; /* in zephyr/dts/arm/nxp/nxp_rt1010.dtsi:14 */
	};

	/* node '/clock-xtal' defined in zephyr/dts/arm/nxp/nxp_rt10xx.dtsi:81 */
	xtal: clock-xtal {
		compatible = "fixed-clock";      /* in zephyr/dts/arm/nxp/nxp_rt10xx.dtsi:82 */
		clock-frequency = < 0x16e3600 >; /* in zephyr/dts/arm/nxp/nxp_rt10xx.dtsi:83 */
		#clock-cells = < 0x0 >;          /* in zephyr/dts/arm/nxp/nxp_rt10xx.dtsi:84 */
		phandle = < 0x3 >;               /* in zephyr/dts/arm/nxp/nxp_rt10xx.dtsi:307 */
	};

	/* node '/clock-rtc-xtal' defined in zephyr/dts/arm/nxp/nxp_rt10xx.dtsi:87 */
	rtc_xtal: clock-rtc-xtal {
		compatible = "fixed-clock";   /* in zephyr/dts/arm/nxp/nxp_rt10xx.dtsi:88 */
		clock-frequency = < 0x8000 >; /* in zephyr/dts/arm/nxp/nxp_rt10xx.dtsi:89 */
		#clock-cells = < 0x0 >;       /* in zephyr/dts/arm/nxp/nxp_rt10xx.dtsi:90 */
		phandle = < 0x4 >;            /* in zephyr/dts/arm/nxp/nxp_rt10xx.dtsi:307 */
	};

	/* node '/usbpll-clock' defined in zephyr/dts/arm/nxp/nxp_rt10xx.dtsi:94 */
	usbclk: usbpll-clock {
		compatible = "fixed-clock";       /* in zephyr/dts/arm/nxp/nxp_rt10xx.dtsi:95 */
		clock-frequency = < 0x1c9c3800 >; /* in zephyr/dts/arm/nxp/nxp_rt10xx.dtsi:96 */
		#clock-cells = < 0x0 >;           /* in zephyr/dts/arm/nxp/nxp_rt10xx.dtsi:97 */
		phandle = < 0x3a >;               /* in zephyr/dts/arm/nxp/nxp_rt10xx.dtsi:891 */
	};

	/* node '/leds' defined in zephyr/boards/nxp/mimxrt1010_evk/mimxrt1010_evk.dts:38 */
	leds {
		compatible = "gpio-leds"; /* in zephyr/boards/nxp/mimxrt1010_evk/mimxrt1010_evk.dts:39 */

		/* node '/leds/led-1' defined in zephyr/boards/nxp/mimxrt1010_evk/mimxrt1010_evk.dts:41 */
		green_led: led-1 {
			gpios = < &gpio1 0xb 0x1 >; /* in zephyr/boards/nxp/mimxrt1010_evk/mimxrt1010_evk.dts:42 */
			label = "User LD1";         /* in zephyr/boards/nxp/mimxrt1010_evk/mimxrt1010_evk.dts:43 */
		};
	};

	/* node '/gpio_keys' defined in zephyr/boards/nxp/mimxrt1010_evk/mimxrt1010_evk.dts:47 */
	gpio_keys {
		compatible = "gpio-keys"; /* in zephyr/boards/nxp/mimxrt1010_evk/mimxrt1010_evk.dts:48 */

		/* node '/gpio_keys/button-1' defined in zephyr/boards/nxp/mimxrt1010_evk/mimxrt1010_evk.dts:50 */
		user_button: button-1 {
			label = "User SW4";          /* in zephyr/boards/nxp/mimxrt1010_evk/mimxrt1010_evk.dts:51 */
			gpios = < &gpio2 0x5 0x11 >; /* in zephyr/boards/nxp/mimxrt1010_evk/mimxrt1010_evk.dts:52 */
			zephyr,code = < 0xb >;       /* in zephyr/boards/nxp/mimxrt1010_evk/mimxrt1010_evk.dts:53 */
		};
	};

	/* node '/connector' defined in zephyr/boards/nxp/mimxrt1010_evk/mimxrt1010_evk.dts:57 */
	arduino_header: connector {
		compatible = "arduino-header-r3";          /* in zephyr/boards/nxp/mimxrt1010_evk/mimxrt1010_evk.dts:58 */
		#gpio-cells = < 0x2 >;                     /* in zephyr/boards/nxp/mimxrt1010_evk/mimxrt1010_evk.dts:59 */
		gpio-map-mask = < 0xffffffff 0xffffffc0 >; /* in zephyr/boards/nxp/mimxrt1010_evk/mimxrt1010_evk.dts:60 */
		gpio-map-pass-thru = < 0x0 0x3f >;         /* in zephyr/boards/nxp/mimxrt1010_evk/mimxrt1010_evk.dts:61 */
		gpio-map = < 0x0 0x0 &gpio1 0x15 0x0 >,
		           < 0x1 0x0 &gpio1 0x17 0x0 >,
		           < 0x2 0x0 &gpio1 0x18 0x0 >,
		           < 0x3 0x0 &gpio1 0x1c 0x0 >,
		           < 0x4 0x0 &gpio1 0xf 0x0 >,
		           < 0x5 0x0 &gpio1 0x10 0x0 >,
		           < 0x6 0x0 &gpio1 0x9 0x0 >,
		           < 0x7 0x0 &gpio1 0xa 0x0 >,
		           < 0x8 0x0 &gpio1 0x13 0x0 >,
		           < 0x9 0x0 &gpio1 0x14 0x0 >,
		           < 0xc 0x0 &gpio1 0xf 0x0 >,
		           < 0xd 0x0 &gpio1 0x10 0x0 >,
		           < 0xe 0x0 &gpio2 0x2 0x0 >,
		           < 0xf 0x0 &gpio2 0x3 0x0 >,
		           < 0x10 0x0 &gpio1 0x13 0x0 >,
		           < 0x11 0x0 &gpio1 0x12 0x0 >,
		           < 0x12 0x0 &gpio1 0x11 0x0 >,
		           < 0x13 0x0 &gpio1 0x14 0x0 >,
		           < 0x14 0x0 &gpio1 0x1 0x0 >,
		           < 0x15 0x0 &gpio1 0x2 0x0 >;    /* in zephyr/boards/nxp/mimxrt1010_evk/mimxrt1010_evk.dts:62 */
	};
};
